AUTOSAR XML (schema 4-2-2)
standard types defined: boolean, float32, float64, sint16, sint32, sint64, sint8, uint16, uint32, uint64, uint8, void
package /BSW/ApplicationDataTypes
  333 x app type, all with category=VALUE:
    BattVolt_LBMR: compu {phys=raw*0.001 for raw 0..65534.99999999999; unit V}, range phys 0..65.535 V
    Day: range phys 0..31 Day
    DrvHeat1Sts: range phys 0..3
    DrvHeat1_pct: range phys 0..127
    DrvHeat2Sts: range phys 0..3
    DrvHeat2_pct: range phys 0..127
    DrvHeat3Sts: range phys 0..3
    DrvHeat3_pct: range phys 0..127
    DrvHeat4Sts: range phys 0..3
    DrvHeat4_pct: range phys 0..127
    DrvHeat5ErrSts: range phys 0..15
    DrvHeat5Sts: range phys 0..3
    DrvHeat5_pct: range phys 0..127
    DrvHeat6Sts: range phys 0..3
    DrvHeat6_pct: range phys 0..127
    DrvKneadingMassgLvlCmd10: range phys 0..3
    DrvKneadingMassgLvlCmd{5..9}: range phys 0..3
    DrvKneadingMassgSkillsCmd10: range phys 0..15
    DrvKneadingMassgSkillsCmd{5..9}: range phys 0..15
    DrvKneadingMassgSkillsSts10: range phys 0..15
    DrvKneadingMassgSkillsSts{5..9}: range phys 0..15
    DrvKneadingMassgTime10: compu {phys=raw*0.1 for raw 0..255}, range phys 0..25.5
    DrvKneadingMassgTime{5..9}: compu {phys=raw*0.1 for raw 0..255}, range phys 0..25.5
    DrvKneadingMassgTimesCmd10: range phys 0..15
    DrvKneadingMassgTimesCmd{5..9}: range phys 0..15
    DrvKneadingMassglvlSts10: range phys 0..3
    DrvKneadingMassglvlSts{5..9}: range phys 0..3
    DrvLumControlSts: range phys 0..7
    DrvLumSwitchSts: range phys 0..7
    DrvLumbarBottomWorkSts: range phys 0..3
    DrvLumbarMidWorkSts: range phys 0..3
    DrvLumbarTopWorkSts: range phys 0..3
    DrvMassSwitchSts: range phys 0..3
    DrvMassageHeatNTC1: compu {phys=raw*0.5-40 for raw -80..175; unit degC}, range phys -40..87.5 degC
    DrvMassageHeatNTC{10..12}: compu {phys=raw*0.5-40 for raw -80..175; unit degC}, range phys -40..87.5 degC
    DrvMassageHeatNTC{2..9}: compu {phys=raw*0.5-40 for raw -80..175; unit degC}, range phys -40..87.5 degC
    DrvPumpCmd: range phys 0..127
    DrvPumpSts: range phys 0..255
    DrvSeatBlosterValueSts: range phys 0..3
    DrvSeatBolsterValueBLCmd: range phys 0..3
    DrvSeatBolsterValueBLPos: range phys 0..255
    DrvSeatBolsterValueBRCmd: range phys 0..3
    DrvSeatBolsterValueBRPos: range phys 0..255
    DrvSeatCushionValue1Cmd: range phys 0..3
    DrvSeatCushionValue1Pos: range phys 0..255
    DrvSeatCushionValue2Cmd: range phys 0..3
    DrvSeatCushionValue2Pos: range phys 0..255
    DrvSeatCushionValue3Cmd: range phys 0..3
    DrvSeatCushionValue3Pos: range phys 0..100
    DrvSeatCushionValue4Cmd: range phys 0..3
    DrvSeatCushionValue4Pos: range phys 0..255
    DrvSeatCushionValue5Cmd: range phys 0..3
    DrvSeatCushionValue5Pos: range phys 0..255
    DrvSeatCushionValue6Cmd: range phys 0..3
    DrvSeatCushionValue6Pos: range phys 0..255
    DrvSeatCushionValueSts: range phys 0..3
    DrvSeatLumbarBottomPos: range phys 0..255
    DrvSeatLumbarBottomValue3Cmd: range phys 0..3
    DrvSeatLumbarMidPos: range phys 0..255
    DrvSeatLumbarMidValue2Cmd: range phys 0..3
    DrvSeatLumbarTopPos: range phys 0..255
    DrvSeatLumbarTopValue1Cmd: range phys 0..3
    DrvSeatLumbarValueSts: range phys 0..3
    DrvSeatMassFailr: range phys 0..1
    DrvSeatUpperValueLCmd: range phys 0..3
    DrvSeatUpperValueLPos: range phys 0..255
    DrvSeatUpperValueMCmd: range phys 0..3
    DrvSeatUpperValueMPos: range phys 0..255
    DrvSeatUpperValueRCmd: range phys 0..3
    DrvSeatUpperValueRPos: range phys 0..255
    DrvSeatUpperValueSts: range phys 0..3
    DrvSeatmassgHeat{10..12}Cmd: range phys 0..3
    DrvSeatmassgHeat{1..9}Cmd: range phys 0..3
    DrvSeatmassgHeatCSts: range phys 0..3
    DrvSeatmassgValve{10..12}Cmd: range phys 0..3
    DrvSeatmassgValve{1..9}Cmd: range phys 0..3
    DrvSeatmassgValveSts: range phys 0..3
    DrvState: range phys 0..7
    DrvState_SrvSts: range phys 0..1
    DrvSystemFailr: range phys 0..1
    Hr: range phys 0..23 Hour
    MSec: range phys 0..1023
    Min: range phys 0..59 min
    Mth: range phys 0..15
    OperatorState: range phys 0..7
    OperatorState_SrvSts: range phys 0..1
    PNC{10..19}_Sts: range phys 0..1
    PNC1_Sts: range phys 0..1
    PNC{20..29}_Sts: range phys 0..1
    PNC2_Sts: range phys 0..1
    PNC{30..39}_Sts: range phys 0..1
    PNC3_Sts: range phys 0..1
    PNC{40..48}_Sts: range phys 0..1
    PNC{4..9}_Sts: range phys 0..1
    PNC_DFT: range phys 0..1
    PassHeat1Sts: range phys 0..3
    PassHeat1_pct: range phys 0..127
    PassHeat2Sts: range phys 0..3
    PassHeat2_pct: range phys 0..127
    PassHeat3Sts: range phys 0..3
    PassHeat3_pct: range phys 0..127
    PassHeat4Sts: range phys 0..3
    PassHeat4_pct: range phys 0..127
    PassHeat5ErrSts: range phys 0..15
    PassHeat5Sts: range phys 0..3
    PassHeat5_pct: range phys 0..127
    PassHeat6Sts: range phys 0..3
    PassHeat6_pct: range phys 0..127
    PassKneadingMassgLvlCmd10: range phys 0..3
    PassKneadingMassgLvlCmd{5..9}: range phys 0..3
    PassKneadingMassgLvlSts10: range phys 0..3
    PassKneadingMassgLvlSts{5..9}: range phys 0..3
    PassKneadingMassgSkillsCmd10: range phys 0..15
    PassKneadingMassgSkillsCmd{5..9}: range phys 0..15
    PassKneadingMassgSkillsSts10: range phys 0..15
    PassKneadingMassgSkillsSts{5..9}: range phys 0..15
    PassKneadingMassgTime10: compu {phys=raw*0.1 for raw 0..255}, range phys 0..25.5
    PassKneadingMassgTime{5..9}: compu {phys=raw*0.1 for raw 0..255}, range phys 0..25.5
    PassKneadingMassgTimesCmd10: range phys 0..15
    PassKneadingMassgTimesCmd{5..9}: range phys 0..15
    PassLumControlSts: range phys 0..7
    PassLumSwitchSts: range phys 0..7
    PassLumbarBottomWorkSts: range phys 0..3
    PassLumbarMidWorkSts: range phys 0..3
    PassLumbarTopWorkSts: range phys 0..3
    PassMassSwitchSts: range phys 0..3
    PassMassageHeatNTC1: compu {phys=raw*0.5-40 for raw -80..175; unit degC}, range phys -40..87.5 degC
    PassMassageHeatNTC{10..12}: compu {phys=raw*0.5-40 for raw -80..175; unit degC}, range phys -40..87.5 degC
    PassMassageHeatNTC{2..9}: compu {phys=raw*0.5-40 for raw -80..175; unit degC}, range phys -40..87.5 degC
    PassPumpCmd: range phys 0..127
    PassPumpSts: range phys 0..255
    PassSeatBlosterValueSts: range phys 0..3
    PassSeatBolsterValueBLCmd: range phys 0..3
    PassSeatBolsterValueBLPos: range phys 0..255
    PassSeatBolsterValueBRCmd: range phys 0..3
    PassSeatBolsterValueBRPos: range phys 0..255
    PassSeatCushionValue1Cmd: range phys 0..3
    PassSeatCushionValue1Pos: range phys 0..255
    PassSeatCushionValue2Cmd: range phys 0..3
    PassSeatCushionValue2Pos: range phys 0..255
    PassSeatCushionValue3Cmd: range phys 0..3
    PassSeatCushionValue3Pos: range phys 0..100
    PassSeatCushionValue4Cmd: range phys 0..3
    PassSeatCushionValue4Pos: range phys 0..255
    PassSeatCushionValue5Cmd: range phys 0..3
    PassSeatCushionValue5Pos: range phys 0..255
    PassSeatCushionValue6Cmd: range phys 0..3
    PassSeatCushionValue6Pos: range phys 0..255
    PassSeatCushionValueSts: range phys 0..3
    PassSeatLumbarBottomPos: range phys 0..255
    PassSeatLumbarBottomValue3Cmd: range phys 0..3
    PassSeatLumbarMidPos: range phys 0..255
    PassSeatLumbarMidValue2Cmd: range phys 0..3
    PassSeatLumbarTopPos: range phys 0..255
    PassSeatLumbarTopValue1Cmd: range phys 0..3
    PassSeatLumbarValueSts: range phys 0..3
    PassSeatMassFailr: range phys 0..1
    PassSeatUpperValueLCmd: range phys 0..3
    PassSeatUpperValueLPos: range phys 0..255
    PassSeatUpperValueMCmd: range phys 0..3
    PassSeatUpperValueMPos: range phys 0..255
    PassSeatUpperValueRCmd: range phys 0..3
    PassSeatUpperValueRPos: range phys 0..255
    PassSeatUpperValueSts: range phys 0..3
    PassSeatmassgHeat{10..12}Cmd: range phys 0..3
    PassSeatmassgHeat{1..9}Cmd: range phys 0..3
    PassSeatmassgHeatCSts: range phys 0..3
    PassSeatmassgValve{10..12}Cmd: range phys 0..3
    PassSeatmassgValve{1..9}Cmd: range phys 0..3
    PassSeatmassgValveSts: range phys 0..3
    PassSystemFailr: range phys 0..1
    Sec: range phys 0..59 min
    VC_Data_5E0_CRC: range phys 0..255
    VC_Data_5E0_MsgCntr: range phys 0..14
    VC_Data_5E0_Payload: range phys 0..281474976710655
    VehModeDef: range phys 0..15
    VehOdometer: range phys 0..16777215 km
    VehSpdSts_Rdnt1: range phys 0..1
    VehSpd_Rdnt1: compu {phys=raw*0.05625 for raw 0..6400; unit km/h}, range phys 0..360 km/h
    VehStateDetailed: range phys 0..15
    VehStateDetailed_SrvSts: range phys 0..1
    Yr: compu {phys=raw+2000 for raw 2000..2254; unit Year}, range phys 2000..2254 Year
    ZONE_13C_CRC: range phys 0..255
    ZONE_13C_MsgCntr: range phys 0..14
    uint16: base-type=uint16
    uint32: base-type=uint32
    uint8: base-type=uint8
package /BSW/CompuMethods
  compu method CM_DrvHeat{1..4}Sts: 0=no_action, 1=action, 2=err, 3=reserved
  compu method CM_DrvHeat5ErrSts: 0=No_Error, 1=Heater_Short_to_GND, 2=Heater_short_to_PWR_or_Heater_Open, 3=Sensor_short_to_GND, 15=Invalid, 4=Sensor_short_to_PWR_or_Sensor_Open, 5=Over_Current
  compu method CM_DrvHeat5Sts: 0=no_action, 1=action, 2=err, 3=reserved
  compu method CM_DrvHeat6Sts: 0=no_action, 1=action, 2=err, 3=reserved
  compu method CM_DrvKneadingMassgLvlCmd10: 0=Idle, 1=intensity_1, 2=intensity_2
  compu method CM_DrvKneadingMassgLvlCmd{5..9}: 0=Idle, 1=intensity_1, 2=intensity_2
  compu method CM_DrvKneadingMassglvlSts10: 0=Idle, 1=intensity_1, 2=intensity_2
  compu method CM_DrvKneadingMassglvlSts{5..9}: 0=Idle, 1=intensity_1, 2=intensity_2
  compu method CM_DrvLumControlSts: 0=No_action, 1=Manual_control, 2=Recall, 3=System_failure, 4=Reserved
  compu method CM_DrvLumSwitchSts: 0=No_Press, 1=Forward, 2=Reward, 3=Up, 4=Down, 5=Erro
  compu method CM_DrvLumbarBottomWorkSts: 0=No_action, 1=Inflation, 2=Deflation, 3=Idle
  compu method CM_DrvLumbarMidWorkSts: 0=No_action, 1=Inflation, 2=Deflation, 3=Idle
  compu method CM_DrvLumbarTopWorkSts: 0=No_action, 1=Inflation, 2=Deflation, 3=Idle
  compu method CM_DrvMassSwitchSts: 0=No_Press, 1=Press, 2=Err, 3=Reserved
  compu method CM_DrvSeatBlosterValueSts: 0=Normal, 1=Action, 2=Err, 3=Reserved
  compu method CM_DrvSeatBolsterValueBLCmd: 0=No_action, 1=Inflation, 2=Deflation, 3=Reserved
  compu method CM_DrvSeatBolsterValueBRCmd: 0=No_action, 1=Inflation, 2=Deflation, 3=Reserved
  compu method CM_DrvSeatCushionValue{1..6}Cmd: 0=No_action, 1=Inflation, 2=Deflation, 3=Reserved
  compu method CM_DrvSeatCushionValueSts: 0=Normal, 1=Action, 2=Err, 3=Reserved
  compu method CM_DrvSeatLumbarBottomValue3Cmd: 0=No_action, 1=Inflation, 2=Deflation, 3=Reserved
  compu method CM_DrvSeatLumbarMidValue2Cmd: 0=No_action, 1=Inflation, 2=Deflation, 3=Reserved
  compu method CM_DrvSeatLumbarTopValue1Cmd: 0=No_action, 1=Inflation, 2=Deflation, 3=Reserved
  compu method CM_DrvSeatLumbarValueSts: 0=Normal, 1=Action, 2=Err, 3=Reserved
  compu method CM_DrvSeatMassFailr: 0=no_Failure, 1=Failure
  compu method CM_DrvSeatUpperValueLCmd: 0=No_action, 1=Inflation, 2=Deflation, 3=Reserved
  compu method CM_DrvSeatUpperValueMCmd: 0=No_action, 1=Inflation, 2=Deflation, 3=Reserved
  compu method CM_DrvSeatUpperValueRCmd: 0=No_action, 1=Inflation, 2=Deflation, 3=Reserved
  compu method CM_DrvSeatUpperValueSts: 0=Normal, 1=Action, 2=Err, 3=Reserved
  compu method CM_DrvSeatmassgHeat{10..12}Cmd: 0=No_action, 1=Heat_open, 2=Heat_Close, 3=Reserved
  compu method CM_DrvSeatmassgHeat{1..9}Cmd: 0=No_action, 1=Heat_open, 2=Heat_Close, 3=Reserved
  compu method CM_DrvSeatmassgHeatCSts: 0=Normal, 1=Action, 2=Err, 3=Reserved
  compu method CM_DrvSeatmassgValve{10..12}Cmd: 0=No_action, 1=Inflation, 2=Deflation, 3=Reserved
  compu method CM_DrvSeatmassgValve{1..9}Cmd: 0=No_action, 1=Inflation, 2=Deflation, 3=Reserved
  compu method CM_DrvSeatmassgValveSts: 0=Normal, 1=Action, 2=Err, 3=Reserved
  compu method CM_DrvState: 0=DRV_ST_NONE, 1=DRV_ST_MD, 2=DRV_ST_AD, 7=DRV_ST_INVALID
  compu method CM_DrvState_SrvSts: 0=invalid, 1=valid
  compu method CM_DrvSystemFailr: 0=no_Failure, 1=Failure
  compu method CM_Mth: 11=November, 12=December, 13=Reserved, 15=Invalid, 0=Unknown, 1=January, 2=February, 3=March, 4=April, 5=May, 6=June, 7=July, 8=August, 9=September, 10=October
  compu method CM_OperatorState: 0=OPERATOR_ST_NONE, 1=OPERATOR_ST_OUTSIDE, 2=OPERATOR_ST_AVAILABLE, 3=OPERATOR_ST_INSIDE, 7=OPERATOR_ST_INVALID
  compu method CM_OperatorState_SrvSts: 0=invalid, 1=valid
  compu method CM_PNC{10..19}_Sts: 0=Inactive, 1=Active
  compu method CM_PNC1_Sts: 0=Inactive, 1=Active
  compu method CM_PNC{20..29}_Sts: 0=Inactive, 1=Active
  compu method CM_PNC2_Sts: 0=Inactive, 1=Active
  compu method CM_PNC{30..39}_Sts: 0=Inactive, 1=Active
  compu method CM_PNC3_Sts: 0=Inactive, 1=Active
  compu method CM_PNC{40..48}_Sts: 0=Inactive, 1=Active
  compu method CM_PNC{4..9}_Sts: 0=Inactive, 1=Active
  compu method CM_PNC_DFT: 0=Inactive, 1=Active
  compu method CM_PassHeat{1..4}Sts: 0=no_action, 1=action, 2=err, 3=reserved
  compu method CM_PassHeat5ErrSts: 0=No_Error, 1=Heater_Short_to_GND, 2=Heater_short_to_PWR_or_Heater_Open, 3=Sensor_short_to_GND, 15=Invalid, 4=Sensor_short_to_PWR_or_Sensor_Open, 5=Over_Current
  compu method CM_PassHeat5Sts: 0=no_action, 1=action, 2=err, 3=reserved
  compu method CM_PassHeat6Sts: 0=no_action, 1=action, 2=err, 3=reserved
  compu method CM_PassKneadingMassgLvlCmd10: 0=Idle, 1=intensity_1, 2=intensity_2
  compu method CM_PassKneadingMassgLvlCmd{5..9}: 0=Idle, 1=intensity_1, 2=intensity_2
  compu method CM_PassKneadingMassgLvlSts10: 0=Idle, 1=intensity_1, 2=intensity_2
  compu method CM_PassKneadingMassgLvlSts{5..9}: 0=Idle, 1=intensity_1, 2=intensity_2
  compu method CM_PassLumControlSts: 0=No_action, 1=Manual_control, 2=Recall, 3=System_failure, 4=Reserved
  compu method CM_PassLumSwitchSts: 0=No_Press, 1=Forward, 2=Reward, 3=Up, 4=Down, 5=Erro
  compu method CM_PassLumbarBottomWorkSts: 0=No_action, 1=Inflation, 2=Deflation, 3=Idle
  compu method CM_PassLumbarMidWorkSts: 0=No_action, 1=Inflation, 2=Deflation, 3=Idle
  compu method CM_PassLumbarTopWorkSts: 0=No_action, 1=Inflation, 2=Deflation, 3=Idle
  compu method CM_PassMassSwitchSts: 0=No_Press, 1=Press, 2=Err, 3=Reserved
  compu method CM_PassSeatBlosterValueSts: 0=Normal, 1=Action, 2=Err, 3=Reserved
  compu method CM_PassSeatBolsterValueBLCmd: 0=No_action, 1=Inflation, 2=Deflation, 3=Reserved
  compu method CM_PassSeatBolsterValueBRCmd: 0=No_action, 1=Inflation, 2=Deflation, 3=Reserved
  compu method CM_PassSeatCushionValue{1..6}Cmd: 0=No_action, 1=Inflation, 2=Deflation, 3=Reserved
  compu method CM_PassSeatCushionValueSts: 0=Normal, 1=Action, 2=Err, 3=Reserved
  compu method CM_PassSeatLumbarBottomValue3Cmd: 0=No_action, 1=Inflation, 2=Deflation, 3=Reserved
  compu method CM_PassSeatLumbarMidValue2Cmd: 0=No_action, 1=Inflation, 2=Deflation, 3=Reserved
  compu method CM_PassSeatLumbarTopValue1Cmd: 0=No_action, 1=Inflation, 2=Deflation, 3=Reserved
  compu method CM_PassSeatLumbarValueSts: 0=Normal, 1=Action, 2=Err, 3=Reserved
  compu method CM_PassSeatMassFailr: 0=no_Failure, 1=Failure
  compu method CM_PassSeatUpperValueLCmd: 0=No_action, 1=Inflation, 2=Deflation, 3=Reserved
  compu method CM_PassSeatUpperValueMCmd: 0=No_action, 1=Inflation, 2=Deflation, 3=Reserved
  compu method CM_PassSeatUpperValueRCmd: 0=No_action, 1=Inflation, 2=Deflation, 3=Reserved
  compu method CM_PassSeatUpperValueSts: 0=Normal, 1=Action, 2=Err, 3=Reserved
  compu method CM_PassSeatmassgHeat{10..12}Cmd: 0=No_action, 1=Heat_open, 2=Heat_Close, 3=Reserved
  compu method CM_PassSeatmassgHeat{1..9}Cmd: 0=No_action, 1=Heat_open, 2=Heat_Close, 3=Reserved
  compu method CM_PassSeatmassgHeatCSts: 0=Normal, 1=Action, 2=Err, 3=Reserved
  compu method CM_PassSeatmassgValve{10..12}Cmd: 0=No_action, 1=Inflation, 2=Deflation, 3=Reserved
  compu method CM_PassSeatmassgValve{1..9}Cmd: 0=No_action, 1=Inflation, 2=Deflation, 3=Reserved
  compu method CM_PassSeatmassgValveSts: 0=Normal, 1=Action, 2=Err, 3=Reserved
  compu method CM_PassSystemFailr: 0=no_Failure, 1=Failure
  compu method CM_VehModeDef: 0=VEHMODE_RESERVED, 1=VEHMODE_PRODUCTION, 2=VEHMODE_TRANSPORT, 3=VEHMODE_SHOWROOM, 15=VEHMODE_INVALID, 4=VEHMODE_REGULAR, 5=VEHMODE_DUT, 6=VEHMODE_TESTDRIVE, 7=VEHMODE_MAINTENANCE, 8=VEHMODE_SVT, 9=VEHMODE_ENDOFLIFE
  compu method CM_VehSpdSts_Rdnt1: 0=Inalid, 1=Valid
  compu method CM_VehStateDetailed: 0=VEH_ST_PARKED, 1=VEH_ST_DRVRDY, 2=VEH_ST_DRIVING, 3=VEH_ST_SWUPDATE, 15=VEH_ST_INVALID, 4=VEH_ST_CHARGING, 5=VEH_ST_PWRSWAP
  compu method CM_VehStateDetailed_SrvSts: 0=invalid, 1=valid
package /BSW/ImplementationDataTypes
  330 x impl type, all with category=VALUE:
    BattVolt_LBMR_IDT: base-type=uint16
    Day_IDT: base-type=uint8
    DrvHeat1Sts_IDT: base-type=uint8
    DrvHeat1_pct_IDT: base-type=uint8
    DrvHeat2Sts_IDT: base-type=uint8
    DrvHeat2_pct_IDT: base-type=uint8
    DrvHeat3Sts_IDT: base-type=uint8
    DrvHeat3_pct_IDT: base-type=uint8
    DrvHeat4Sts_IDT: base-type=uint8
    DrvHeat4_pct_IDT: base-type=uint8
    DrvHeat5ErrSts_IDT: base-type=uint8
    DrvHeat5Sts_IDT: base-type=uint8
    DrvHeat5_pct_IDT: base-type=uint8
    DrvHeat6Sts_IDT: base-type=uint8
    DrvHeat6_pct_IDT: base-type=uint8
    DrvKneadingMassgLvlCmd10_IDT: base-type=uint8
    DrvKneadingMassgLvlCmd{5..9}_IDT: base-type=uint8
    DrvKneadingMassgSkillsCmd10_IDT: base-type=uint8
    DrvKneadingMassgSkillsCmd{5..9}_IDT: base-type=uint8
    DrvKneadingMassgSkillsSts10_IDT: base-type=uint8
    DrvKneadingMassgSkillsSts{5..9}_IDT: base-type=uint8
    DrvKneadingMassgTime10_IDT: base-type=uint8
    DrvKneadingMassgTime{5..9}_IDT: base-type=uint8
    DrvKneadingMassgTimesCmd10_IDT: base-type=uint8
    DrvKneadingMassgTimesCmd{5..9}_IDT: base-type=uint8
    DrvKneadingMassglvlSts10_IDT: base-type=uint8
    DrvKneadingMassglvlSts{5..9}_IDT: base-type=uint8
    DrvLumControlSts_IDT: base-type=uint8
    DrvLumSwitchSts_IDT: base-type=uint8
    DrvLumbarBottomWorkSts_IDT: base-type=uint8
    DrvLumbarMidWorkSts_IDT: base-type=uint8
    DrvLumbarTopWorkSts_IDT: base-type=uint8
    DrvMassSwitchSts_IDT: base-type=uint8
    DrvMassageHeatNTC{10..12}_IDT: base-type=uint8
    DrvMassageHeatNTC{1..9}_IDT: base-type=uint8
    DrvPumpCmd_IDT: base-type=uint8
    DrvPumpSts_IDT: base-type=uint8
    DrvSeatBlosterValueSts_IDT: base-type=uint8
    DrvSeatBolsterValueBLCmd_IDT: base-type=uint8
    DrvSeatBolsterValueBLPos_IDT: base-type=uint8
    DrvSeatBolsterValueBRCmd_IDT: base-type=uint8
    DrvSeatBolsterValueBRPos_IDT: base-type=uint8
    DrvSeatCushionValue1Cmd_IDT: base-type=uint8
    DrvSeatCushionValue1Pos_IDT: base-type=uint8
    DrvSeatCushionValue2Cmd_IDT: base-type=uint8
    DrvSeatCushionValue2Pos_IDT: base-type=uint8
    DrvSeatCushionValue3Cmd_IDT: base-type=uint8
    DrvSeatCushionValue3Pos_IDT: base-type=uint8
    DrvSeatCushionValue4Cmd_IDT: base-type=uint8
    DrvSeatCushionValue4Pos_IDT: base-type=uint8
    DrvSeatCushionValue5Cmd_IDT: base-type=uint8
    DrvSeatCushionValue5Pos_IDT: base-type=uint8
    DrvSeatCushionValue6Cmd_IDT: base-type=uint8
    DrvSeatCushionValue6Pos_IDT: base-type=uint8
    DrvSeatCushionValueSts_IDT: base-type=uint8
    DrvSeatLumbarBottomPos_IDT: base-type=uint8
    DrvSeatLumbarBottomValue3Cmd_IDT: base-type=uint8
    DrvSeatLumbarMidPos_IDT: base-type=uint8
    DrvSeatLumbarMidValue2Cmd_IDT: base-type=uint8
    DrvSeatLumbarTopPos_IDT: base-type=uint8
    DrvSeatLumbarTopValue1Cmd_IDT: base-type=uint8
    DrvSeatLumbarValueSts_IDT: base-type=uint8
    DrvSeatMassFailr_IDT: base-type=uint8
    DrvSeatUpperValueLCmd_IDT: base-type=uint8
    DrvSeatUpperValueLPos_IDT: base-type=uint8
    DrvSeatUpperValueMCmd_IDT: base-type=uint8
    DrvSeatUpperValueMPos_IDT: base-type=uint8
    DrvSeatUpperValueRCmd_IDT: base-type=uint8
    DrvSeatUpperValueRPos_IDT: base-type=uint8
    DrvSeatUpperValueSts_IDT: base-type=uint8
    DrvSeatmassgHeat{10..12}Cmd_IDT: base-type=uint8
    DrvSeatmassgHeat{1..9}Cmd_IDT: base-type=uint8
    DrvSeatmassgHeatCSts_IDT: base-type=uint8
    DrvSeatmassgValve{10..12}Cmd_IDT: base-type=uint8
    DrvSeatmassgValve{1..9}Cmd_IDT: base-type=uint8
    DrvSeatmassgValveSts_IDT: base-type=uint8
    DrvState_IDT: base-type=uint8
    DrvState_SrvSts_IDT: base-type=uint8
    DrvSystemFailr_IDT: base-type=uint8
    Hr_IDT: base-type=uint8
    MSec_IDT: base-type=uint16
    Min_IDT: base-type=uint8
    Mth_IDT: base-type=uint8
    OperatorState_IDT: base-type=uint8
    OperatorState_SrvSts_IDT: base-type=uint8
    PNC{10..19}_Sts_IDT: base-type=uint8
    PNC1_Sts_IDT: base-type=uint8
    PNC{20..29}_Sts_IDT: base-type=uint8
    PNC2_Sts_IDT: base-type=uint8
    PNC{30..39}_Sts_IDT: base-type=uint8
    PNC3_Sts_IDT: base-type=uint8
    PNC{40..48}_Sts_IDT: base-type=uint8
    PNC{4..9}_Sts_IDT: base-type=uint8
    PNC_DFT_IDT: base-type=uint8
    PassHeat1Sts_IDT: base-type=uint8
    PassHeat1_pct_IDT: base-type=uint8
    PassHeat2Sts_IDT: base-type=uint8
    PassHeat2_pct_IDT: base-type=uint8
    PassHeat3Sts_IDT: base-type=uint8
    PassHeat3_pct_IDT: base-type=uint8
    PassHeat4Sts_IDT: base-type=uint8
    PassHeat4_pct_IDT: base-type=uint8
    PassHeat5ErrSts_IDT: base-type=uint8
    PassHeat5Sts_IDT: base-type=uint8
    PassHeat5_pct_IDT: base-type=uint8
    PassHeat6Sts_IDT: base-type=uint8
    PassHeat6_pct_IDT: base-type=uint8
    PassKneadingMassgLvlCmd10_IDT: base-type=uint8
    PassKneadingMassgLvlCmd{5..9}_IDT: base-type=uint8
    PassKneadingMassgLvlSts10_IDT: base-type=uint8
    PassKneadingMassgLvlSts{5..9}_IDT: base-type=uint8
    PassKneadingMassgSkillsCmd10_IDT: base-type=uint8
    PassKneadingMassgSkillsCmd{5..9}_IDT: base-type=uint8
    PassKneadingMassgSkillsSts10_IDT: base-type=uint8
    PassKneadingMassgSkillsSts{5..9}_IDT: base-type=uint8
    PassKneadingMassgTime10_IDT: base-type=uint8
    PassKneadingMassgTime{5..9}_IDT: base-type=uint8
    PassKneadingMassgTimesCmd10_IDT: base-type=uint8
    PassKneadingMassgTimesCmd{5..9}_IDT: base-type=uint8
    PassLumControlSts_IDT: base-type=uint8
    PassLumSwitchSts_IDT: base-type=uint8
    PassLumbarBottomWorkSts_IDT: base-type=uint8
    PassLumbarMidWorkSts_IDT: base-type=uint8
    PassLumbarTopWorkSts_IDT: base-type=uint8
    PassMassSwitchSts_IDT: base-type=uint8
    PassMassageHeatNTC{10..12}_IDT: base-type=uint8
    PassMassageHeatNTC{1..9}_IDT: base-type=uint8
    PassPumpCmd_IDT: base-type=uint8
    PassPumpSts_IDT: base-type=uint8
    PassSeatBlosterValueSts_IDT: base-type=uint8
    PassSeatBolsterValueBLCmd_IDT: base-type=uint8
    PassSeatBolsterValueBLPos_IDT: base-type=uint8
    PassSeatBolsterValueBRCmd_IDT: base-type=uint8
    PassSeatBolsterValueBRPos_IDT: base-type=uint8
    PassSeatCushionValue1Cmd_IDT: base-type=uint8
    PassSeatCushionValue1Pos_IDT: base-type=uint8
    PassSeatCushionValue2Cmd_IDT: base-type=uint8
    PassSeatCushionValue2Pos_IDT: base-type=uint8
    PassSeatCushionValue3Cmd_IDT: base-type=uint8
    PassSeatCushionValue3Pos_IDT: base-type=uint8
    PassSeatCushionValue4Cmd_IDT: base-type=uint8
    PassSeatCushionValue4Pos_IDT: base-type=uint8
    PassSeatCushionValue5Cmd_IDT: base-type=uint8
    PassSeatCushionValue5Pos_IDT: base-type=uint8
    PassSeatCushionValue6Cmd_IDT: base-type=uint8
    PassSeatCushionValue6Pos_IDT: base-type=uint8
    PassSeatCushionValueSts_IDT: base-type=uint8
    PassSeatLumbarBottomPos_IDT: base-type=uint8
    PassSeatLumbarBottomValue3Cmd_IDT: base-type=uint8
    PassSeatLumbarMidPos_IDT: base-type=uint8
    PassSeatLumbarMidValue2Cmd_IDT: base-type=uint8
    PassSeatLumbarTopPos_IDT: base-type=uint8
    PassSeatLumbarTopValue1Cmd_IDT: base-type=uint8
    PassSeatLumbarValueSts_IDT: base-type=uint8
    PassSeatMassFailr_IDT: base-type=uint8
    PassSeatUpperValueLCmd_IDT: base-type=uint8
    PassSeatUpperValueLPos_IDT: base-type=uint8
    PassSeatUpperValueMCmd_IDT: base-type=uint8
    PassSeatUpperValueMPos_IDT: base-type=uint8
    PassSeatUpperValueRCmd_IDT: base-type=uint8
    PassSeatUpperValueRPos_IDT: base-type=uint8
    PassSeatUpperValueSts_IDT: base-type=uint8
    PassSeatmassgHeat{10..12}Cmd_IDT: base-type=uint8
    PassSeatmassgHeat{1..9}Cmd_IDT: base-type=uint8
    PassSeatmassgHeatCSts_IDT: base-type=uint8
    PassSeatmassgValve{10..12}Cmd_IDT: base-type=uint8
    PassSeatmassgValve{1..9}Cmd_IDT: base-type=uint8
    PassSeatmassgValveSts_IDT: base-type=uint8
    PassSystemFailr_IDT: base-type=uint8
    Sec_IDT: base-type=uint8
    VC_Data_5E0_CRC_IDT: base-type=uint8
    VC_Data_5E0_MsgCntr_IDT: base-type=uint8
    VC_Data_5E0_Payload_IDT: base-type=uint64
    VehModeDef_IDT: base-type=uint8
    VehOdometer_IDT: base-type=uint32
    VehSpdSts_Rdnt1_IDT: base-type=uint8
    VehSpd_Rdnt1_IDT: base-type=uint16
    VehStateDetailed_IDT: base-type=uint8
    VehStateDetailed_SrvSts_IDT: base-type=uint8
    Yr_IDT: base-type=uint8
    ZONE_13C_CRC_IDT: base-type=uint8
    ZONE_13C_MsgCntr_IDT: base-type=uint8
package /BSW/Units
  9 x unit:
    Day: display-name=Day
    Hour: display-name=Hour
    Sec: display-name=Sec
    V: display-name=V
    VehSpd_Rdnt1: display-name=km/h
    Year: display-name=Year
    degC: display-name=degC
    km: display-name=km
    min: display-name=min
package /BSW/PortInterfaces
  330 x sender receiver interface, all with service-kind=ANY-STANDARDIZED:
    BattVolt_LBMR
      data BattVolt_LBMR: type=BattVolt_LBMR
    Day
      data Day: type=Day
    DrvHeat1Sts
      data DrvHeat1Sts: type=DrvHeat1Sts
    DrvHeat1_pct
      data DrvHeat1_pct: type=DrvHeat1_pct
    DrvHeat2Sts
      data DrvHeat2Sts: type=DrvHeat2Sts
    DrvHeat2_pct
      data DrvHeat2_pct: type=DrvHeat2_pct
    DrvHeat3Sts
      data DrvHeat3Sts: type=DrvHeat3Sts
    DrvHeat3_pct
      data DrvHeat3_pct: type=DrvHeat3_pct
    DrvHeat4Sts
      data DrvHeat4Sts: type=DrvHeat4Sts
    DrvHeat4_pct
      data DrvHeat4_pct: type=DrvHeat4_pct
    DrvHeat5ErrSts
      data DrvHeat5ErrSts: type=DrvHeat5ErrSts
    DrvHeat5Sts
      data DrvHeat5Sts: type=DrvHeat5Sts
    DrvHeat5_pct
      data DrvHeat5_pct: type=DrvHeat5_pct
    DrvHeat6Sts
      data DrvHeat6Sts: type=DrvHeat6Sts
    DrvHeat6_pct
      data DrvHeat6_pct: type=DrvHeat6_pct
    DrvKneadingMassgLvlCmd10
      data DrvKneadingMassgLvlCmd10: type=DrvKneadingMassgLvlCmd10
    DrvKneadingMassgLvlCmd5
      data DrvKneadingMassgLvlCmd5: type=DrvKneadingMassgLvlCmd5
    DrvKneadingMassgLvlCmd6
      data DrvKneadingMassgLvlCmd6: type=DrvKneadingMassgLvlCmd6
    DrvKneadingMassgLvlCmd7
      data DrvKneadingMassgLvlCmd7: type=DrvKneadingMassgLvlCmd7
    DrvKneadingMassgLvlCmd8
      data DrvKneadingMassgLvlCmd8: type=DrvKneadingMassgLvlCmd8
    DrvKneadingMassgLvlCmd9
      data DrvKneadingMassgLvlCmd9: type=DrvKneadingMassgLvlCmd9
    DrvKneadingMassgSkillsCmd10
      data DrvKneadingMassgSkillsCmd10: type=DrvKneadingMassgSkillsCmd10
    DrvKneadingMassgSkillsCmd5
      data DrvKneadingMassgSkillsCmd5: type=DrvKneadingMassgSkillsCmd5
    DrvKneadingMassgSkillsCmd6
      data DrvKneadingMassgSkillsCmd6: type=DrvKneadingMassgSkillsCmd6
    DrvKneadingMassgSkillsCmd7
      data DrvKneadingMassgSkillsCmd7: type=DrvKneadingMassgSkillsCmd7
    DrvKneadingMassgSkillsCmd8
      data DrvKneadingMassgSkillsCmd8: type=DrvKneadingMassgSkillsCmd8
    DrvKneadingMassgSkillsCmd9
      data DrvKneadingMassgSkillsCmd9: type=DrvKneadingMassgSkillsCmd9
    DrvKneadingMassgSkillsSts10
      data DrvKneadingMassgSkillsSts10: type=DrvKneadingMassgSkillsSts10
    DrvKneadingMassgSkillsSts5
      data DrvKneadingMassgSkillsSts5: type=DrvKneadingMassgSkillsSts5
    DrvKneadingMassgSkillsSts6
      data DrvKneadingMassgSkillsSts6: type=DrvKneadingMassgSkillsSts6
    DrvKneadingMassgSkillsSts7
      data DrvKneadingMassgSkillsSts7: type=DrvKneadingMassgSkillsSts7
    DrvKneadingMassgSkillsSts8
      data DrvKneadingMassgSkillsSts8: type=DrvKneadingMassgSkillsSts8
    DrvKneadingMassgSkillsSts9
      data DrvKneadingMassgSkillsSts9: type=DrvKneadingMassgSkillsSts9
    DrvKneadingMassgTime10
      data DrvKneadingMassgTime10: type=DrvKneadingMassgTime10
    DrvKneadingMassgTime5
      data DrvKneadingMassgTime5: type=DrvKneadingMassgTime5
    DrvKneadingMassgTime6
      data DrvKneadingMassgTime6: type=DrvKneadingMassgTime6
    DrvKneadingMassgTime7
      data DrvKneadingMassgTime7: type=DrvKneadingMassgTime7
    DrvKneadingMassgTime8
      data DrvKneadingMassgTime8: type=DrvKneadingMassgTime8
    DrvKneadingMassgTime9
      data DrvKneadingMassgTime9: type=DrvKneadingMassgTime9
    DrvKneadingMassgTimesCmd10
      data DrvKneadingMassgTimesCmd10: type=DrvKneadingMassgTimesCmd10
    DrvKneadingMassgTimesCmd5
      data DrvKneadingMassgTimesCmd5: type=DrvKneadingMassgTimesCmd5
    DrvKneadingMassgTimesCmd6
      data DrvKneadingMassgTimesCmd6: type=DrvKneadingMassgTimesCmd6
    DrvKneadingMassgTimesCmd7
      data DrvKneadingMassgTimesCmd7: type=DrvKneadingMassgTimesCmd7
    DrvKneadingMassgTimesCmd8
      data DrvKneadingMassgTimesCmd8: type=DrvKneadingMassgTimesCmd8
    DrvKneadingMassgTimesCmd9
      data DrvKneadingMassgTimesCmd9: type=DrvKneadingMassgTimesCmd9
    DrvKneadingMassglvlSts10
      data DrvKneadingMassglvlSts10: type=DrvKneadingMassglvlSts10
    DrvKneadingMassglvlSts5
      data DrvKneadingMassglvlSts5: type=DrvKneadingMassglvlSts5
    DrvKneadingMassglvlSts6
      data DrvKneadingMassglvlSts6: type=DrvKneadingMassglvlSts6
    DrvKneadingMassglvlSts7
      data DrvKneadingMassglvlSts7: type=DrvKneadingMassglvlSts7
    DrvKneadingMassglvlSts8
      data DrvKneadingMassglvlSts8: type=DrvKneadingMassglvlSts8
    DrvKneadingMassglvlSts9
      data DrvKneadingMassglvlSts9: type=DrvKneadingMassglvlSts9
    DrvLumControlSts
      data DrvLumControlSts: type=DrvLumControlSts
    DrvLumSwitchSts
      data DrvLumSwitchSts: type=DrvLumSwitchSts
    DrvLumbarBottomWorkSts
      data DrvLumbarBottomWorkSts: type=DrvLumbarBottomWorkSts
    DrvLumbarMidWorkSts
      data DrvLumbarMidWorkSts: type=DrvLumbarMidWorkSts
    DrvLumbarTopWorkSts
      data DrvLumbarTopWorkSts: type=DrvLumbarTopWorkSts
    DrvMassSwitchSts
      data DrvMassSwitchSts: type=DrvMassSwitchSts
    DrvMassageHeatNTC1
      data DrvMassageHeatNTC1: type=DrvMassageHeatNTC1
    DrvMassageHeatNTC10
      data DrvMassageHeatNTC10: type=DrvMassageHeatNTC10
    DrvMassageHeatNTC11
      data DrvMassageHeatNTC11: type=DrvMassageHeatNTC11
    DrvMassageHeatNTC12
      data DrvMassageHeatNTC12: type=DrvMassageHeatNTC12
    DrvMassageHeatNTC2
      data DrvMassageHeatNTC2: type=DrvMassageHeatNTC2
    DrvMassageHeatNTC3
      data DrvMassageHeatNTC3: type=DrvMassageHeatNTC3
    DrvMassageHeatNTC4
      data DrvMassageHeatNTC4: type=DrvMassageHeatNTC4
    DrvMassageHeatNTC5
      data DrvMassageHeatNTC5: type=DrvMassageHeatNTC5
    DrvMassageHeatNTC6
      data DrvMassageHeatNTC6: type=DrvMassageHeatNTC6
    DrvMassageHeatNTC7
      data DrvMassageHeatNTC7: type=DrvMassageHeatNTC7
    DrvMassageHeatNTC8
      data DrvMassageHeatNTC8: type=DrvMassageHeatNTC8
    DrvMassageHeatNTC9
      data DrvMassageHeatNTC9: type=DrvMassageHeatNTC9
    DrvPumpCmd
      data DrvPumpCmd: type=DrvPumpCmd
    DrvPumpSts
      data DrvPumpSts: type=DrvPumpSts
    DrvSeatBlosterValueSts
      data DrvSeatBlosterValueSts: type=DrvSeatBlosterValueSts
    DrvSeatBolsterValueBLCmd
      data DrvSeatBolsterValueBLCmd: type=DrvSeatBolsterValueBLCmd
    DrvSeatBolsterValueBLPos
      data DrvSeatBolsterValueBLPos: type=DrvSeatBolsterValueBLPos
    DrvSeatBolsterValueBRCmd
      data DrvSeatBolsterValueBRCmd: type=DrvSeatBolsterValueBRCmd
    DrvSeatBolsterValueBRPos
      data DrvSeatBolsterValueBRPos: type=DrvSeatBolsterValueBRPos
    DrvSeatCushionValue1Cmd
      data DrvSeatCushionValue1Cmd: type=DrvSeatCushionValue1Cmd
    DrvSeatCushionValue1Pos
      data DrvSeatCushionValue1Pos: type=DrvSeatCushionValue1Pos
    DrvSeatCushionValue2Cmd
      data DrvSeatCushionValue2Cmd: type=DrvSeatCushionValue2Cmd
    DrvSeatCushionValue2Pos
      data DrvSeatCushionValue2Pos: type=DrvSeatCushionValue2Pos
    DrvSeatCushionValue3Cmd
      data DrvSeatCushionValue3Cmd: type=DrvSeatCushionValue3Cmd
    DrvSeatCushionValue3Pos
      data DrvSeatCushionValue3Pos: type=DrvSeatCushionValue3Pos
    DrvSeatCushionValue4Cmd
      data DrvSeatCushionValue4Cmd: type=DrvSeatCushionValue4Cmd
    DrvSeatCushionValue4Pos
      data DrvSeatCushionValue4Pos: type=DrvSeatCushionValue4Pos
    DrvSeatCushionValue5Cmd
      data DrvSeatCushionValue5Cmd: type=DrvSeatCushionValue5Cmd
    DrvSeatCushionValue5Pos
      data DrvSeatCushionValue5Pos: type=DrvSeatCushionValue5Pos
    DrvSeatCushionValue6Cmd
      data DrvSeatCushionValue6Cmd: type=DrvSeatCushionValue6Cmd
    DrvSeatCushionValue6Pos
      data DrvSeatCushionValue6Pos: type=DrvSeatCushionValue6Pos
    DrvSeatCushionValueSts
      data DrvSeatCushionValueSts: type=DrvSeatCushionValueSts
    DrvSeatLumbarBottomPos
      data DrvSeatLumbarBottomPos: type=DrvSeatLumbarBottomPos
    DrvSeatLumbarBottomValue3Cmd
      data DrvSeatLumbarBottomValue3Cmd: type=DrvSeatLumbarBottomValue3Cmd
    DrvSeatLumbarMidPos
      data DrvSeatLumbarMidPos: type=DrvSeatLumbarMidPos
    DrvSeatLumbarMidValue2Cmd
      data DrvSeatLumbarMidValue2Cmd: type=DrvSeatLumbarMidValue2Cmd
    DrvSeatLumbarTopPos
      data DrvSeatLumbarTopPos: type=DrvSeatLumbarTopPos
    DrvSeatLumbarTopValue1Cmd
      data DrvSeatLumbarTopValue1Cmd: type=DrvSeatLumbarTopValue1Cmd
    DrvSeatLumbarValueSts
      data DrvSeatLumbarValueSts: type=DrvSeatLumbarValueSts
    DrvSeatMassFailr
      data DrvSeatMassFailr: type=DrvSeatMassFailr
    DrvSeatUpperValueLCmd
      data DrvSeatUpperValueLCmd: type=DrvSeatUpperValueLCmd
    DrvSeatUpperValueLPos
      data DrvSeatUpperValueLPos: type=DrvSeatUpperValueLPos
    DrvSeatUpperValueMCmd
      data DrvSeatUpperValueMCmd: type=DrvSeatUpperValueMCmd
    DrvSeatUpperValueMPos
      data DrvSeatUpperValueMPos: type=DrvSeatUpperValueMPos
    DrvSeatUpperValueRCmd
      data DrvSeatUpperValueRCmd: type=DrvSeatUpperValueRCmd
    DrvSeatUpperValueRPos
      data DrvSeatUpperValueRPos: type=DrvSeatUpperValueRPos
    DrvSeatUpperValueSts
      data DrvSeatUpperValueSts: type=DrvSeatUpperValueSts
    DrvSeatmassgHeat10Cmd
      data DrvSeatmassgHeat10Cmd: type=DrvSeatmassgHeat10Cmd
    DrvSeatmassgHeat11Cmd
      data DrvSeatmassgHeat11Cmd: type=DrvSeatmassgHeat11Cmd
    DrvSeatmassgHeat12Cmd
      data DrvSeatmassgHeat12Cmd: type=DrvSeatmassgHeat12Cmd
    DrvSeatmassgHeat1Cmd
      data DrvSeatmassgHeat1Cmd: type=DrvSeatmassgHeat1Cmd
    DrvSeatmassgHeat2Cmd
      data DrvSeatmassgHeat2Cmd: type=DrvSeatmassgHeat2Cmd
    DrvSeatmassgHeat3Cmd
      data DrvSeatmassgHeat3Cmd: type=DrvSeatmassgHeat3Cmd
    DrvSeatmassgHeat4Cmd
      data DrvSeatmassgHeat4Cmd: type=DrvSeatmassgHeat4Cmd
    DrvSeatmassgHeat5Cmd
      data DrvSeatmassgHeat5Cmd: type=DrvSeatmassgHeat5Cmd
    DrvSeatmassgHeat6Cmd
      data DrvSeatmassgHeat6Cmd: type=DrvSeatmassgHeat6Cmd
    DrvSeatmassgHeat7Cmd
      data DrvSeatmassgHeat7Cmd: type=DrvSeatmassgHeat7Cmd
    DrvSeatmassgHeat8Cmd
      data DrvSeatmassgHeat8Cmd: type=DrvSeatmassgHeat8Cmd
    DrvSeatmassgHeat9Cmd
      data DrvSeatmassgHeat9Cmd: type=DrvSeatmassgHeat9Cmd
    DrvSeatmassgHeatCSts
      data DrvSeatmassgHeatCSts: type=DrvSeatmassgHeatCSts
    DrvSeatmassgValve10Cmd
      data DrvSeatmassgValve10Cmd: type=DrvSeatmassgValve10Cmd
    DrvSeatmassgValve11Cmd
      data DrvSeatmassgValve11Cmd: type=DrvSeatmassgValve11Cmd
    DrvSeatmassgValve12Cmd
      data DrvSeatmassgValve12Cmd: type=DrvSeatmassgValve12Cmd
    DrvSeatmassgValve1Cmd
      data DrvSeatmassgValve1Cmd: type=DrvSeatmassgValve1Cmd
    DrvSeatmassgValve2Cmd
      data DrvSeatmassgValve2Cmd: type=DrvSeatmassgValve2Cmd
    DrvSeatmassgValve3Cmd
      data DrvSeatmassgValve3Cmd: type=DrvSeatmassgValve3Cmd
    DrvSeatmassgValve4Cmd
      data DrvSeatmassgValve4Cmd: type=DrvSeatmassgValve4Cmd
    DrvSeatmassgValve5Cmd
      data DrvSeatmassgValve5Cmd: type=DrvSeatmassgValve5Cmd
    DrvSeatmassgValve6Cmd
      data DrvSeatmassgValve6Cmd: type=DrvSeatmassgValve6Cmd
    DrvSeatmassgValve7Cmd
      data DrvSeatmassgValve7Cmd: type=DrvSeatmassgValve7Cmd
    DrvSeatmassgValve8Cmd
      data DrvSeatmassgValve8Cmd: type=DrvSeatmassgValve8Cmd
    DrvSeatmassgValve9Cmd
      data DrvSeatmassgValve9Cmd: type=DrvSeatmassgValve9Cmd
    DrvSeatmassgValveSts
      data DrvSeatmassgValveSts: type=DrvSeatmassgValveSts
    DrvState
      data DrvState: type=DrvState
    DrvState_SrvSts
      data DrvState_SrvSts: type=DrvState_SrvSts
    DrvSystemFailr
      data DrvSystemFailr: type=DrvSystemFailr
    Hr
      data Hr: type=Hr
    MSec
      data MSec: type=MSec
    Min
      data Min: type=Min
    Mth
      data Mth: type=Mth
    OperatorState
      data OperatorState: type=OperatorState
    OperatorState_SrvSts
      data OperatorState_SrvSts: type=OperatorState_SrvSts
    PNC10_Sts
      data PNC10_Sts: type=PNC10_Sts
    PNC11_Sts
      data PNC11_Sts: type=PNC11_Sts
    PNC12_Sts
      data PNC12_Sts: type=PNC12_Sts
    PNC13_Sts
      data PNC13_Sts: type=PNC13_Sts
    PNC14_Sts
      data PNC14_Sts: type=PNC14_Sts
    PNC15_Sts
      data PNC15_Sts: type=PNC15_Sts
    PNC16_Sts
      data PNC16_Sts: type=PNC16_Sts
    PNC17_Sts
      data PNC17_Sts: type=PNC17_Sts
    PNC18_Sts
      data PNC18_Sts: type=PNC18_Sts
    PNC19_Sts
      data PNC19_Sts: type=PNC19_Sts
    PNC1_Sts
      data PNC1_Sts: type=PNC1_Sts
    PNC20_Sts
      data PNC20_Sts: type=PNC20_Sts
    PNC21_Sts
      data PNC21_Sts: type=PNC21_Sts
    PNC22_Sts
      data PNC22_Sts: type=PNC22_Sts
    PNC23_Sts
      data PNC23_Sts: type=PNC23_Sts
    PNC24_Sts
      data PNC24_Sts: type=PNC24_Sts
    PNC25_Sts
      data PNC25_Sts: type=PNC25_Sts
    PNC26_Sts
      data PNC26_Sts: type=PNC26_Sts
    PNC27_Sts
      data PNC27_Sts: type=PNC27_Sts
    PNC28_Sts
      data PNC28_Sts: type=PNC28_Sts
    PNC29_Sts
      data PNC29_Sts: type=PNC29_Sts
    PNC2_Sts
      data PNC2_Sts: type=PNC2_Sts
    PNC30_Sts
      data PNC30_Sts: type=PNC30_Sts
    PNC31_Sts
      data PNC31_Sts: type=PNC31_Sts
    PNC32_Sts
      data PNC32_Sts: type=PNC32_Sts
    PNC33_Sts
      data PNC33_Sts: type=PNC33_Sts
    PNC34_Sts
      data PNC34_Sts: type=PNC34_Sts
    PNC35_Sts
      data PNC35_Sts: type=PNC35_Sts
    PNC36_Sts
      data PNC36_Sts: type=PNC36_Sts
    PNC37_Sts
      data PNC37_Sts: type=PNC37_Sts
    PNC38_Sts
      data PNC38_Sts: type=PNC38_Sts
    PNC39_Sts
      data PNC39_Sts: type=PNC39_Sts
    PNC3_Sts
      data PNC3_Sts: type=PNC3_Sts
    PNC40_Sts
      data PNC40_Sts: type=PNC40_Sts
    PNC41_Sts
      data PNC41_Sts: type=PNC41_Sts
    PNC42_Sts
      data PNC42_Sts: type=PNC42_Sts
    PNC43_Sts
      data PNC43_Sts: type=PNC43_Sts
    PNC44_Sts
      data PNC44_Sts: type=PNC44_Sts
    PNC45_Sts
      data PNC45_Sts: type=PNC45_Sts
    PNC46_Sts
      data PNC46_Sts: type=PNC46_Sts
    PNC47_Sts
      data PNC47_Sts: type=PNC47_Sts
    PNC48_Sts
      data PNC48_Sts: type=PNC48_Sts
    PNC4_Sts
      data PNC4_Sts: type=PNC4_Sts
    PNC5_Sts
      data PNC5_Sts: type=PNC5_Sts
    PNC6_Sts
      data PNC6_Sts: type=PNC6_Sts
    PNC7_Sts
      data PNC7_Sts: type=PNC7_Sts
    PNC8_Sts
      data PNC8_Sts: type=PNC8_Sts
    PNC9_Sts
      data PNC9_Sts: type=PNC9_Sts
    PNC_DFT
      data PNC_DFT: type=PNC_DFT
    PassHeat1Sts
      data PassHeat1Sts: type=PassHeat1Sts
    PassHeat1_pct
      data PassHeat1_pct: type=PassHeat1_pct
    PassHeat2Sts
      data PassHeat2Sts: type=PassHeat2Sts
    PassHeat2_pct
      data PassHeat2_pct: type=PassHeat2_pct
    PassHeat3Sts
      data PassHeat3Sts: type=PassHeat3Sts
    PassHeat3_pct
      data PassHeat3_pct: type=PassHeat3_pct
    PassHeat4Sts
      data PassHeat4Sts: type=PassHeat4Sts
    PassHeat4_pct
      data PassHeat4_pct: type=PassHeat4_pct
    PassHeat5ErrSts
      data PassHeat5ErrSts: type=PassHeat5ErrSts
    PassHeat5Sts
      data PassHeat5Sts: type=PassHeat5Sts
    PassHeat5_pct
      data PassHeat5_pct: type=PassHeat5_pct
    PassHeat6Sts
      data PassHeat6Sts: type=PassHeat6Sts
    PassHeat6_pct
      data PassHeat6_pct: type=PassHeat6_pct
    PassKneadingMassgLvlCmd10
      data PassKneadingMassgLvlCmd10: type=PassKneadingMassgLvlCmd10
    PassKneadingMassgLvlCmd5
      data PassKneadingMassgLvlCmd5: type=PassKneadingMassgLvlCmd5
    PassKneadingMassgLvlCmd6
      data PassKneadingMassgLvlCmd6: type=PassKneadingMassgLvlCmd6
    PassKneadingMassgLvlCmd7
      data PassKneadingMassgLvlCmd7: type=PassKneadingMassgLvlCmd7
    PassKneadingMassgLvlCmd8
      data PassKneadingMassgLvlCmd8: type=PassKneadingMassgLvlCmd8
    PassKneadingMassgLvlCmd9
      data PassKneadingMassgLvlCmd9: type=PassKneadingMassgLvlCmd9
    PassKneadingMassgLvlSts10
      data PassKneadingMassgLvlSts10: type=PassKneadingMassgLvlSts10
    PassKneadingMassgLvlSts5
      data PassKneadingMassgLvlSts5: type=PassKneadingMassgLvlSts5
    PassKneadingMassgLvlSts6
      data PassKneadingMassgLvlSts6: type=PassKneadingMassgLvlSts6
    PassKneadingMassgLvlSts7
      data PassKneadingMassgLvlSts7: type=PassKneadingMassgLvlSts7
    PassKneadingMassgLvlSts8
      data PassKneadingMassgLvlSts8: type=PassKneadingMassgLvlSts8
    PassKneadingMassgLvlSts9
      data PassKneadingMassgLvlSts9: type=PassKneadingMassgLvlSts9
    PassKneadingMassgSkillsCmd10
      data PassKneadingMassgSkillsCmd10: type=PassKneadingMassgSkillsCmd10
    PassKneadingMassgSkillsCmd5
      data PassKneadingMassgSkillsCmd5: type=PassKneadingMassgSkillsCmd5
    PassKneadingMassgSkillsCmd6
      data PassKneadingMassgSkillsCmd6: type=PassKneadingMassgSkillsCmd6
    PassKneadingMassgSkillsCmd7
      data PassKneadingMassgSkillsCmd7: type=PassKneadingMassgSkillsCmd7
    PassKneadingMassgSkillsCmd8
      data PassKneadingMassgSkillsCmd8: type=PassKneadingMassgSkillsCmd8
    PassKneadingMassgSkillsCmd9
      data PassKneadingMassgSkillsCmd9: type=PassKneadingMassgSkillsCmd9
    PassKneadingMassgSkillsSts10
      data PassKneadingMassgSkillsSts10: type=PassKneadingMassgSkillsSts10
    PassKneadingMassgSkillsSts5
      data PassKneadingMassgSkillsSts5: type=PassKneadingMassgSkillsSts5
    PassKneadingMassgSkillsSts6
      data PassKneadingMassgSkillsSts6: type=PassKneadingMassgSkillsSts6
    PassKneadingMassgSkillsSts7
      data PassKneadingMassgSkillsSts7: type=PassKneadingMassgSkillsSts7
    PassKneadingMassgSkillsSts8
      data PassKneadingMassgSkillsSts8: type=PassKneadingMassgSkillsSts8
    PassKneadingMassgSkillsSts9
      data PassKneadingMassgSkillsSts9: type=PassKneadingMassgSkillsSts9
    PassKneadingMassgTime10
      data PassKneadingMassgTime10: type=PassKneadingMassgTime10
    PassKneadingMassgTime5
      data PassKneadingMassgTime5: type=PassKneadingMassgTime5
    PassKneadingMassgTime6
      data PassKneadingMassgTime6: type=PassKneadingMassgTime6
    PassKneadingMassgTime7
      data PassKneadingMassgTime7: type=PassKneadingMassgTime7
    PassKneadingMassgTime8
      data PassKneadingMassgTime8: type=PassKneadingMassgTime8
    PassKneadingMassgTime9
      data PassKneadingMassgTime9: type=PassKneadingMassgTime9
    PassKneadingMassgTimesCmd10
      data PassKneadingMassgTimesCmd10: type=PassKneadingMassgTimesCmd10
    PassKneadingMassgTimesCmd5
      data PassKneadingMassgTimesCmd5: type=PassKneadingMassgTimesCmd5
    PassKneadingMassgTimesCmd6
      data PassKneadingMassgTimesCmd6: type=PassKneadingMassgTimesCmd6
    PassKneadingMassgTimesCmd7
      data PassKneadingMassgTimesCmd7: type=PassKneadingMassgTimesCmd7
    PassKneadingMassgTimesCmd8
      data PassKneadingMassgTimesCmd8: type=PassKneadingMassgTimesCmd8
    PassKneadingMassgTimesCmd9
      data PassKneadingMassgTimesCmd9: type=PassKneadingMassgTimesCmd9
    PassLumControlSts
      data PassLumControlSts: type=PassLumControlSts
    PassLumSwitchSts
      data PassLumSwitchSts: type=PassLumSwitchSts
    PassLumbarBottomWorkSts
      data PassLumbarBottomWorkSts: type=PassLumbarBottomWorkSts
    PassLumbarMidWorkSts
      data PassLumbarMidWorkSts: type=PassLumbarMidWorkSts
    PassLumbarTopWorkSts
      data PassLumbarTopWorkSts: type=PassLumbarTopWorkSts
    PassMassSwitchSts
      data PassMassSwitchSts: type=PassMassSwitchSts
    PassMassageHeatNTC1
      data PassMassageHeatNTC1: type=PassMassageHeatNTC1
    PassMassageHeatNTC10
      data PassMassageHeatNTC10: type=PassMassageHeatNTC10
    PassMassageHeatNTC11
      data PassMassageHeatNTC11: type=PassMassageHeatNTC11
    PassMassageHeatNTC12
      data PassMassageHeatNTC12: type=PassMassageHeatNTC12
    PassMassageHeatNTC2
      data PassMassageHeatNTC2: type=PassMassageHeatNTC2
    PassMassageHeatNTC3
      data PassMassageHeatNTC3: type=PassMassageHeatNTC3
    PassMassageHeatNTC4
      data PassMassageHeatNTC4: type=PassMassageHeatNTC4
    PassMassageHeatNTC5
      data PassMassageHeatNTC5: type=PassMassageHeatNTC5
    PassMassageHeatNTC6
      data PassMassageHeatNTC6: type=PassMassageHeatNTC6
    PassMassageHeatNTC7
      data PassMassageHeatNTC7: type=PassMassageHeatNTC7
    PassMassageHeatNTC8
      data PassMassageHeatNTC8: type=PassMassageHeatNTC8
    PassMassageHeatNTC9
      data PassMassageHeatNTC9: type=PassMassageHeatNTC9
    PassPumpCmd
      data PassPumpCmd: type=PassPumpCmd
    PassPumpSts
      data PassPumpSts: type=PassPumpSts
    PassSeatBlosterValueSts
      data PassSeatBlosterValueSts: type=PassSeatBlosterValueSts
    PassSeatBolsterValueBLCmd
      data PassSeatBolsterValueBLCmd: type=PassSeatBolsterValueBLCmd
    PassSeatBolsterValueBLPos
      data PassSeatBolsterValueBLPos: type=PassSeatBolsterValueBLPos
    PassSeatBolsterValueBRCmd
      data PassSeatBolsterValueBRCmd: type=PassSeatBolsterValueBRCmd
    PassSeatBolsterValueBRPos
      data PassSeatBolsterValueBRPos: type=PassSeatBolsterValueBRPos
    PassSeatCushionValue1Cmd
      data PassSeatCushionValue1Cmd: type=PassSeatCushionValue1Cmd
    PassSeatCushionValue1Pos
      data PassSeatCushionValue1Pos: type=PassSeatCushionValue1Pos
    PassSeatCushionValue2Cmd
      data PassSeatCushionValue2Cmd: type=PassSeatCushionValue2Cmd
    PassSeatCushionValue2Pos
      data PassSeatCushionValue2Pos: type=PassSeatCushionValue2Pos
    PassSeatCushionValue3Cmd
      data PassSeatCushionValue3Cmd: type=PassSeatCushionValue3Cmd
    PassSeatCushionValue3Pos
      data PassSeatCushionValue3Pos: type=PassSeatCushionValue3Pos
    PassSeatCushionValue4Cmd
      data PassSeatCushionValue4Cmd: type=PassSeatCushionValue4Cmd
    PassSeatCushionValue4Pos
      data PassSeatCushionValue4Pos: type=PassSeatCushionValue4Pos
    PassSeatCushionValue5Cmd
      data PassSeatCushionValue5Cmd: type=PassSeatCushionValue5Cmd
    PassSeatCushionValue5Pos
      data PassSeatCushionValue5Pos: type=PassSeatCushionValue5Pos
    PassSeatCushionValue6Cmd
      data PassSeatCushionValue6Cmd: type=PassSeatCushionValue6Cmd
    PassSeatCushionValue6Pos
      data PassSeatCushionValue6Pos: type=PassSeatCushionValue6Pos
    PassSeatCushionValueSts
      data PassSeatCushionValueSts: type=PassSeatCushionValueSts
    PassSeatLumbarBottomPos
      data PassSeatLumbarBottomPos: type=PassSeatLumbarBottomPos
    PassSeatLumbarBottomValue3Cmd
      data PassSeatLumbarBottomValue3Cmd: type=PassSeatLumbarBottomValue3Cmd
    PassSeatLumbarMidPos
      data PassSeatLumbarMidPos: type=PassSeatLumbarMidPos
    PassSeatLumbarMidValue2Cmd
      data PassSeatLumbarMidValue2Cmd: type=PassSeatLumbarMidValue2Cmd
    PassSeatLumbarTopPos
      data PassSeatLumbarTopPos: type=PassSeatLumbarTopPos
    PassSeatLumbarTopValue1Cmd
      data PassSeatLumbarTopValue1Cmd: type=PassSeatLumbarTopValue1Cmd
    PassSeatLumbarValueSts
      data PassSeatLumbarValueSts: type=PassSeatLumbarValueSts
    PassSeatMassFailr
      data PassSeatMassFailr: type=PassSeatMassFailr
    PassSeatUpperValueLCmd
      data PassSeatUpperValueLCmd: type=PassSeatUpperValueLCmd
    PassSeatUpperValueLPos
      data PassSeatUpperValueLPos: type=PassSeatUpperValueLPos
    PassSeatUpperValueMCmd
      data PassSeatUpperValueMCmd: type=PassSeatUpperValueMCmd
    PassSeatUpperValueMPos
      data PassSeatUpperValueMPos: type=PassSeatUpperValueMPos
    PassSeatUpperValueRCmd
      data PassSeatUpperValueRCmd: type=PassSeatUpperValueRCmd
    PassSeatUpperValueRPos
      data PassSeatUpperValueRPos: type=PassSeatUpperValueRPos
    PassSeatUpperValueSts
      data PassSeatUpperValueSts: type=PassSeatUpperValueSts
    PassSeatmassgHeat10Cmd
      data PassSeatmassgHeat10Cmd: type=PassSeatmassgHeat10Cmd
    PassSeatmassgHeat11Cmd
      data PassSeatmassgHeat11Cmd: type=PassSeatmassgHeat11Cmd
    PassSeatmassgHeat12Cmd
      data PassSeatmassgHeat12Cmd: type=PassSeatmassgHeat12Cmd
    PassSeatmassgHeat1Cmd
      data PassSeatmassgHeat1Cmd: type=PassSeatmassgHeat1Cmd
    PassSeatmassgHeat2Cmd
      data PassSeatmassgHeat2Cmd: type=PassSeatmassgHeat2Cmd
    PassSeatmassgHeat3Cmd
      data PassSeatmassgHeat3Cmd: type=PassSeatmassgHeat3Cmd
    PassSeatmassgHeat4Cmd
      data PassSeatmassgHeat4Cmd: type=PassSeatmassgHeat4Cmd
    PassSeatmassgHeat5Cmd
      data PassSeatmassgHeat5Cmd: type=PassSeatmassgHeat5Cmd
    PassSeatmassgHeat6Cmd
      data PassSeatmassgHeat6Cmd: type=PassSeatmassgHeat6Cmd
    PassSeatmassgHeat7Cmd
      data PassSeatmassgHeat7Cmd: type=PassSeatmassgHeat7Cmd
    PassSeatmassgHeat8Cmd
      data PassSeatmassgHeat8Cmd: type=PassSeatmassgHeat8Cmd
    PassSeatmassgHeat9Cmd
      data PassSeatmassgHeat9Cmd: type=PassSeatmassgHeat9Cmd
    PassSeatmassgHeatCSts
      data PassSeatmassgHeatCSts: type=PassSeatmassgHeatCSts
    PassSeatmassgValve10Cmd
      data PassSeatmassgValve10Cmd: type=PassSeatmassgValve10Cmd
    PassSeatmassgValve11Cmd
      data PassSeatmassgValve11Cmd: type=PassSeatmassgValve11Cmd
    PassSeatmassgValve12Cmd
      data PassSeatmassgValve12Cmd: type=PassSeatmassgValve12Cmd
    PassSeatmassgValve1Cmd
      data PassSeatmassgValve1Cmd: type=PassSeatmassgValve1Cmd
    PassSeatmassgValve2Cmd
      data PassSeatmassgValve2Cmd: type=PassSeatmassgValve2Cmd
    PassSeatmassgValve3Cmd
      data PassSeatmassgValve3Cmd: type=PassSeatmassgValve3Cmd
    PassSeatmassgValve4Cmd
      data PassSeatmassgValve4Cmd: type=PassSeatmassgValve4Cmd
    PassSeatmassgValve5Cmd
      data PassSeatmassgValve5Cmd: type=PassSeatmassgValve5Cmd
    PassSeatmassgValve6Cmd
      data PassSeatmassgValve6Cmd: type=PassSeatmassgValve6Cmd
    PassSeatmassgValve7Cmd
      data PassSeatmassgValve7Cmd: type=PassSeatmassgValve7Cmd
    PassSeatmassgValve8Cmd
      data PassSeatmassgValve8Cmd: type=PassSeatmassgValve8Cmd
    PassSeatmassgValve9Cmd
      data PassSeatmassgValve9Cmd: type=PassSeatmassgValve9Cmd
    PassSeatmassgValveSts
      data PassSeatmassgValveSts: type=PassSeatmassgValveSts
    PassSystemFailr
      data PassSystemFailr: type=PassSystemFailr
    Sec
      data Sec: type=Sec
    VC_Data_5E0_CRC
      data VC_Data_5E0_CRC: type=VC_Data_5E0_CRC
    VC_Data_5E0_MsgCntr
      data VC_Data_5E0_MsgCntr: type=VC_Data_5E0_MsgCntr
    VC_Data_5E0_Payload
      data VC_Data_5E0_Payload: type=VC_Data_5E0_Payload
    VehModeDef
      data VehModeDef: type=VehModeDef
    VehOdometer
      data VehOdometer: type=VehOdometer
    VehSpdSts_Rdnt1
      data VehSpdSts_Rdnt1: type=VehSpdSts_Rdnt1
    VehSpd_Rdnt1
      data VehSpd_Rdnt1: type=VehSpd_Rdnt1
    VehStateDetailed
      data VehStateDetailed: type=VehStateDetailed
    VehStateDetailed_SrvSts
      data VehStateDetailed_SrvSts: type=VehStateDetailed_SrvSts
    Yr
      data Yr: type=Yr
    ZONE_13C_CRC
      data ZONE_13C_CRC: type=ZONE_13C_CRC
    ZONE_13C_MsgCntr
      data ZONE_13C_MsgCntr: type=ZONE_13C_MsgCntr
package /BSW/DataTypeMappingSets
  data type mapping set DataTypeMappingSet
    data-type-maps:
      application-data-type=BattVolt_LBMR, implementation-data-type=BattVolt_LBMR_IDT
      application-data-type=Day, implementation-data-type=Day_IDT
      application-data-type=DrvHeat1Sts, implementation-data-type=DrvHeat1Sts_IDT
      application-data-type=DrvHeat1_pct, implementation-data-type=DrvHeat1_pct_IDT
      application-data-type=DrvHeat2Sts, implementation-data-type=DrvHeat2Sts_IDT
      application-data-type=DrvHeat2_pct, implementation-data-type=DrvHeat2_pct_IDT
      application-data-type=DrvHeat3Sts, implementation-data-type=DrvHeat3Sts_IDT
      application-data-type=DrvHeat3_pct, implementation-data-type=DrvHeat3_pct_IDT
      application-data-type=DrvHeat4Sts, implementation-data-type=DrvHeat4Sts_IDT
      application-data-type=DrvHeat4_pct, implementation-data-type=DrvHeat4_pct_IDT
      application-data-type=DrvHeat5ErrSts, implementation-data-type=DrvHeat5ErrSts_IDT
      application-data-type=DrvHeat5Sts, implementation-data-type=DrvHeat5Sts_IDT
      application-data-type=DrvHeat5_pct, implementation-data-type=DrvHeat5_pct_IDT
      application-data-type=DrvHeat6Sts, implementation-data-type=DrvHeat6Sts_IDT
      application-data-type=DrvHeat6_pct, implementation-data-type=DrvHeat6_pct_IDT
      application-data-type=DrvKneadingMassgLvlCmd10, implementation-data-type=DrvKneadingMassgLvlCmd10_IDT
      application-data-type=DrvKneadingMassgLvlCmd{5..9}, implementation-data-type=DrvKneadingMassgLvlCmd{5..9}_IDT
      application-data-type=DrvKneadingMassgSkillsCmd10, implementation-data-type=DrvKneadingMassgSkillsCmd10_IDT
      application-data-type=DrvKneadingMassgSkillsCmd{5..9}, implementation-data-type=DrvKneadingMassgSkillsCmd{5..9}_IDT
      application-data-type=DrvKneadingMassgSkillsSts10, implementation-data-type=DrvKneadingMassgSkillsSts10_IDT
      application-data-type=DrvKneadingMassgSkillsSts{5..9}, implementation-data-type=DrvKneadingMassgSkillsSts{5..9}_IDT
      application-data-type=DrvKneadingMassgTime10, implementation-data-type=DrvKneadingMassgTime10_IDT
      application-data-type=DrvKneadingMassgTime{5..9}, implementation-data-type=DrvKneadingMassgTime{5..9}_IDT
      application-data-type=DrvKneadingMassgTimesCmd10, implementation-data-type=DrvKneadingMassgTimesCmd10_IDT
      application-data-type=DrvKneadingMassgTimesCmd{5..9}, implementation-data-type=DrvKneadingMassgTimesCmd{5..9}_IDT
      application-data-type=DrvKneadingMassglvlSts10, implementation-data-type=DrvKneadingMassglvlSts10_IDT
      application-data-type=DrvKneadingMassglvlSts{5..9}, implementation-data-type=DrvKneadingMassglvlSts{5..9}_IDT
      application-data-type=DrvLumControlSts, implementation-data-type=DrvLumControlSts_IDT
      application-data-type=DrvLumSwitchSts, implementation-data-type=DrvLumSwitchSts_IDT
      application-data-type=DrvLumbarBottomWorkSts, implementation-data-type=DrvLumbarBottomWorkSts_IDT
      application-data-type=DrvLumbarMidWorkSts, implementation-data-type=DrvLumbarMidWorkSts_IDT
      application-data-type=DrvLumbarTopWorkSts, implementation-data-type=DrvLumbarTopWorkSts_IDT
      application-data-type=DrvMassSwitchSts, implementation-data-type=DrvMassSwitchSts_IDT
      application-data-type=DrvMassageHeatNTC1, implementation-data-type=DrvMassageHeatNTC1_IDT
      application-data-type=DrvMassageHeatNTC{10..12}, implementation-data-type=DrvMassageHeatNTC{10..12}_IDT
      application-data-type=DrvMassageHeatNTC{2..9}, implementation-data-type=DrvMassageHeatNTC{2..9}_IDT
      application-data-type=DrvPumpCmd, implementation-data-type=DrvPumpCmd_IDT
      application-data-type=DrvPumpSts, implementation-data-type=DrvPumpSts_IDT
      application-data-type=DrvSeatBlosterValueSts, implementation-data-type=DrvSeatBlosterValueSts_IDT
      application-data-type=DrvSeatBolsterValueBLCmd, implementation-data-type=DrvSeatBolsterValueBLCmd_IDT
      application-data-type=DrvSeatBolsterValueBLPos, implementation-data-type=DrvSeatBolsterValueBLPos_IDT
      application-data-type=DrvSeatBolsterValueBRCmd, implementation-data-type=DrvSeatBolsterValueBRCmd_IDT
      application-data-type=DrvSeatBolsterValueBRPos, implementation-data-type=DrvSeatBolsterValueBRPos_IDT
      application-data-type=DrvSeatCushionValue1Cmd, implementation-data-type=DrvSeatCushionValue1Cmd_IDT
      application-data-type=DrvSeatCushionValue1Pos, implementation-data-type=DrvSeatCushionValue1Pos_IDT
      application-data-type=DrvSeatCushionValue2Cmd, implementation-data-type=DrvSeatCushionValue2Cmd_IDT
      application-data-type=DrvSeatCushionValue2Pos, implementation-data-type=DrvSeatCushionValue2Pos_IDT
      application-data-type=DrvSeatCushionValue3Cmd, implementation-data-type=DrvSeatCushionValue3Cmd_IDT
      application-data-type=DrvSeatCushionValue3Pos, implementation-data-type=DrvSeatCushionValue3Pos_IDT
      application-data-type=DrvSeatCushionValue4Cmd, implementation-data-type=DrvSeatCushionValue4Cmd_IDT
      application-data-type=DrvSeatCushionValue4Pos, implementation-data-type=DrvSeatCushionValue4Pos_IDT
      application-data-type=DrvSeatCushionValue5Cmd, implementation-data-type=DrvSeatCushionValue5Cmd_IDT
      application-data-type=DrvSeatCushionValue5Pos, implementation-data-type=DrvSeatCushionValue5Pos_IDT
      application-data-type=DrvSeatCushionValue6Cmd, implementation-data-type=DrvSeatCushionValue6Cmd_IDT
      application-data-type=DrvSeatCushionValue6Pos, implementation-data-type=DrvSeatCushionValue6Pos_IDT
      application-data-type=DrvSeatCushionValueSts, implementation-data-type=DrvSeatCushionValueSts_IDT
      application-data-type=DrvSeatLumbarBottomPos, implementation-data-type=DrvSeatLumbarBottomPos_IDT
      application-data-type=DrvSeatLumbarBottomValue3Cmd, implementation-data-type=DrvSeatLumbarBottomValue3Cmd_IDT
      application-data-type=DrvSeatLumbarMidPos, implementation-data-type=DrvSeatLumbarMidPos_IDT
      application-data-type=DrvSeatLumbarMidValue2Cmd, implementation-data-type=DrvSeatLumbarMidValue2Cmd_IDT
      application-data-type=DrvSeatLumbarTopPos, implementation-data-type=DrvSeatLumbarTopPos_IDT
      application-data-type=DrvSeatLumbarTopValue1Cmd, implementation-data-type=DrvSeatLumbarTopValue1Cmd_IDT
      application-data-type=DrvSeatLumbarValueSts, implementation-data-type=DrvSeatLumbarValueSts_IDT
      application-data-type=DrvSeatMassFailr, implementation-data-type=DrvSeatMassFailr_IDT
      application-data-type=DrvSeatUpperValueLCmd, implementation-data-type=DrvSeatUpperValueLCmd_IDT
      application-data-type=DrvSeatUpperValueLPos, implementation-data-type=DrvSeatUpperValueLPos_IDT
      application-data-type=DrvSeatUpperValueMCmd, implementation-data-type=DrvSeatUpperValueMCmd_IDT
      application-data-type=DrvSeatUpperValueMPos, implementation-data-type=DrvSeatUpperValueMPos_IDT
      application-data-type=DrvSeatUpperValueRCmd, implementation-data-type=DrvSeatUpperValueRCmd_IDT
      application-data-type=DrvSeatUpperValueRPos, implementation-data-type=DrvSeatUpperValueRPos_IDT
      application-data-type=DrvSeatUpperValueSts, implementation-data-type=DrvSeatUpperValueSts_IDT
      application-data-type=DrvSeatmassgHeat{10..12}Cmd, implementation-data-type=DrvSeatmassgHeat{10..12}Cmd_IDT
      application-data-type=DrvSeatmassgHeat{1..9}Cmd, implementation-data-type=DrvSeatmassgHeat{1..9}Cmd_IDT
      application-data-type=DrvSeatmassgHeatCSts, implementation-data-type=DrvSeatmassgHeatCSts_IDT
      application-data-type=DrvSeatmassgValve{10..12}Cmd, implementation-data-type=DrvSeatmassgValve{10..12}Cmd_IDT
      application-data-type=DrvSeatmassgValve{1..9}Cmd, implementation-data-type=DrvSeatmassgValve{1..9}Cmd_IDT
      application-data-type=DrvSeatmassgValveSts, implementation-data-type=DrvSeatmassgValveSts_IDT
      application-data-type=DrvState, implementation-data-type=DrvState_IDT
      application-data-type=DrvState_SrvSts, implementation-data-type=DrvState_SrvSts_IDT
      application-data-type=DrvSystemFailr, implementation-data-type=DrvSystemFailr_IDT
      application-data-type=Hr, implementation-data-type=Hr_IDT
      application-data-type=MSec, implementation-data-type=MSec_IDT
      application-data-type=Min, implementation-data-type=Min_IDT
      application-data-type=Mth, implementation-data-type=Mth_IDT
      application-data-type=OperatorState, implementation-data-type=OperatorState_IDT
      application-data-type=OperatorState_SrvSts, implementation-data-type=OperatorState_SrvSts_IDT
      application-data-type=PNC{10..19}_Sts, implementation-data-type=PNC{10..19}_Sts_IDT
      application-data-type=PNC1_Sts, implementation-data-type=PNC1_Sts_IDT
      application-data-type=PNC{20..29}_Sts, implementation-data-type=PNC{20..29}_Sts_IDT
      application-data-type=PNC2_Sts, implementation-data-type=PNC2_Sts_IDT
      application-data-type=PNC{30..39}_Sts, implementation-data-type=PNC{30..39}_Sts_IDT
      application-data-type=PNC3_Sts, implementation-data-type=PNC3_Sts_IDT
      application-data-type=PNC{40..48}_Sts, implementation-data-type=PNC{40..48}_Sts_IDT
      application-data-type=PNC{4..9}_Sts, implementation-data-type=PNC{4..9}_Sts_IDT
      application-data-type=PNC_DFT, implementation-data-type=PNC_DFT_IDT
      application-data-type=PassHeat1Sts, implementation-data-type=PassHeat1Sts_IDT
      application-data-type=PassHeat1_pct, implementation-data-type=PassHeat1_pct_IDT
      application-data-type=PassHeat2Sts, implementation-data-type=PassHeat2Sts_IDT
      application-data-type=PassHeat2_pct, implementation-data-type=PassHeat2_pct_IDT
      application-data-type=PassHeat3Sts, implementation-data-type=PassHeat3Sts_IDT
      application-data-type=PassHeat3_pct, implementation-data-type=PassHeat3_pct_IDT
      application-data-type=PassHeat4Sts, implementation-data-type=PassHeat4Sts_IDT
      application-data-type=PassHeat4_pct, implementation-data-type=PassHeat4_pct_IDT
      application-data-type=PassHeat5ErrSts, implementation-data-type=PassHeat5ErrSts_IDT
      application-data-type=PassHeat5Sts, implementation-data-type=PassHeat5Sts_IDT
      application-data-type=PassHeat5_pct, implementation-data-type=PassHeat5_pct_IDT
      application-data-type=PassHeat6Sts, implementation-data-type=PassHeat6Sts_IDT
      application-data-type=PassHeat6_pct, implementation-data-type=PassHeat6_pct_IDT
      application-data-type=PassKneadingMassgLvlCmd10, implementation-data-type=PassKneadingMassgLvlCmd10_IDT
      application-data-type=PassKneadingMassgLvlCmd{5..9}, implementation-data-type=PassKneadingMassgLvlCmd{5..9}_IDT
      application-data-type=PassKneadingMassgLvlSts10, implementation-data-type=PassKneadingMassgLvlSts10_IDT
      application-data-type=PassKneadingMassgLvlSts{5..9}, implementation-data-type=PassKneadingMassgLvlSts{5..9}_IDT
      application-data-type=PassKneadingMassgSkillsCmd10, implementation-data-type=PassKneadingMassgSkillsCmd10_IDT
      application-data-type=PassKneadingMassgSkillsCmd{5..9}, implementation-data-type=PassKneadingMassgSkillsCmd{5..9}_IDT
      application-data-type=PassKneadingMassgSkillsSts10, implementation-data-type=PassKneadingMassgSkillsSts10_IDT
      application-data-type=PassKneadingMassgSkillsSts{5..9}, implementation-data-type=PassKneadingMassgSkillsSts{5..9}_IDT
      application-data-type=PassKneadingMassgTime10, implementation-data-type=PassKneadingMassgTime10_IDT
      application-data-type=PassKneadingMassgTime{5..9}, implementation-data-type=PassKneadingMassgTime{5..9}_IDT
      application-data-type=PassKneadingMassgTimesCmd10, implementation-data-type=PassKneadingMassgTimesCmd10_IDT
      application-data-type=PassKneadingMassgTimesCmd{5..9}, implementation-data-type=PassKneadingMassgTimesCmd{5..9}_IDT
      application-data-type=PassLumControlSts, implementation-data-type=PassLumControlSts_IDT
      application-data-type=PassLumSwitchSts, implementation-data-type=PassLumSwitchSts_IDT
      application-data-type=PassLumbarBottomWorkSts, implementation-data-type=PassLumbarBottomWorkSts_IDT
      application-data-type=PassLumbarMidWorkSts, implementation-data-type=PassLumbarMidWorkSts_IDT
      application-data-type=PassLumbarTopWorkSts, implementation-data-type=PassLumbarTopWorkSts_IDT
      application-data-type=PassMassSwitchSts, implementation-data-type=PassMassSwitchSts_IDT
      application-data-type=PassMassageHeatNTC1, implementation-data-type=PassMassageHeatNTC1_IDT
      application-data-type=PassMassageHeatNTC{10..12}, implementation-data-type=PassMassageHeatNTC{10..12}_IDT
      application-data-type=PassMassageHeatNTC{2..9}, implementation-data-type=PassMassageHeatNTC{2..9}_IDT
      application-data-type=PassPumpCmd, implementation-data-type=PassPumpCmd_IDT
      application-data-type=PassPumpSts, implementation-data-type=PassPumpSts_IDT
      application-data-type=PassSeatBlosterValueSts, implementation-data-type=PassSeatBlosterValueSts_IDT
      application-data-type=PassSeatBolsterValueBLCmd, implementation-data-type=PassSeatBolsterValueBLCmd_IDT
      application-data-type=PassSeatBolsterValueBLPos, implementation-data-type=PassSeatBolsterValueBLPos_IDT
      application-data-type=PassSeatBolsterValueBRCmd, implementation-data-type=PassSeatBolsterValueBRCmd_IDT
      application-data-type=PassSeatBolsterValueBRPos, implementation-data-type=PassSeatBolsterValueBRPos_IDT
      application-data-type=PassSeatCushionValue1Cmd, implementation-data-type=PassSeatCushionValue1Cmd_IDT
      application-data-type=PassSeatCushionValue1Pos, implementation-data-type=PassSeatCushionValue1Pos_IDT
      application-data-type=PassSeatCushionValue2Cmd, implementation-data-type=PassSeatCushionValue2Cmd_IDT
      application-data-type=PassSeatCushionValue2Pos, implementation-data-type=PassSeatCushionValue2Pos_IDT
      application-data-type=PassSeatCushionValue3Cmd, implementation-data-type=PassSeatCushionValue3Cmd_IDT
      application-data-type=PassSeatCushionValue3Pos, implementation-data-type=PassSeatCushionValue3Pos_IDT
      application-data-type=PassSeatCushionValue4Cmd, implementation-data-type=PassSeatCushionValue4Cmd_IDT
      application-data-type=PassSeatCushionValue4Pos, implementation-data-type=PassSeatCushionValue4Pos_IDT
      application-data-type=PassSeatCushionValue5Cmd, implementation-data-type=PassSeatCushionValue5Cmd_IDT
      application-data-type=PassSeatCushionValue5Pos, implementation-data-type=PassSeatCushionValue5Pos_IDT
      application-data-type=PassSeatCushionValue6Cmd, implementation-data-type=PassSeatCushionValue6Cmd_IDT
      application-data-type=PassSeatCushionValue6Pos, implementation-data-type=PassSeatCushionValue6Pos_IDT
      application-data-type=PassSeatCushionValueSts, implementation-data-type=PassSeatCushionValueSts_IDT
      application-data-type=PassSeatLumbarBottomPos, implementation-data-type=PassSeatLumbarBottomPos_IDT
      application-data-type=PassSeatLumbarBottomValue3Cmd, implementation-data-type=PassSeatLumbarBottomValue3Cmd_IDT
      application-data-type=PassSeatLumbarMidPos, implementation-data-type=PassSeatLumbarMidPos_IDT
      application-data-type=PassSeatLumbarMidValue2Cmd, implementation-data-type=PassSeatLumbarMidValue2Cmd_IDT
      application-data-type=PassSeatLumbarTopPos, implementation-data-type=PassSeatLumbarTopPos_IDT
      application-data-type=PassSeatLumbarTopValue1Cmd, implementation-data-type=PassSeatLumbarTopValue1Cmd_IDT
      application-data-type=PassSeatLumbarValueSts, implementation-data-type=PassSeatLumbarValueSts_IDT
      application-data-type=PassSeatMassFailr, implementation-data-type=PassSeatMassFailr_IDT
      application-data-type=PassSeatUpperValueLCmd, implementation-data-type=PassSeatUpperValueLCmd_IDT
      application-data-type=PassSeatUpperValueLPos, implementation-data-type=PassSeatUpperValueLPos_IDT
      application-data-type=PassSeatUpperValueMCmd, implementation-data-type=PassSeatUpperValueMCmd_IDT
      application-data-type=PassSeatUpperValueMPos, implementation-data-type=PassSeatUpperValueMPos_IDT
      application-data-type=PassSeatUpperValueRCmd, implementation-data-type=PassSeatUpperValueRCmd_IDT
      application-data-type=PassSeatUpperValueRPos, implementation-data-type=PassSeatUpperValueRPos_IDT
      application-data-type=PassSeatUpperValueSts, implementation-data-type=PassSeatUpperValueSts_IDT
      application-data-type=PassSeatmassgHeat{10..12}Cmd, implementation-data-type=PassSeatmassgHeat{10..12}Cmd_IDT
      application-data-type=PassSeatmassgHeat{1..9}Cmd, implementation-data-type=PassSeatmassgHeat{1..9}Cmd_IDT
      application-data-type=PassSeatmassgHeatCSts, implementation-data-type=PassSeatmassgHeatCSts_IDT
      application-data-type=PassSeatmassgValve{10..12}Cmd, implementation-data-type=PassSeatmassgValve{10..12}Cmd_IDT
      application-data-type=PassSeatmassgValve{1..9}Cmd, implementation-data-type=PassSeatmassgValve{1..9}Cmd_IDT
      application-data-type=PassSeatmassgValveSts, implementation-data-type=PassSeatmassgValveSts_IDT
      application-data-type=PassSystemFailr, implementation-data-type=PassSystemFailr_IDT
      application-data-type=Sec, implementation-data-type=Sec_IDT
      application-data-type=VC_Data_5E0_CRC, implementation-data-type=VC_Data_5E0_CRC_IDT
      application-data-type=VC_Data_5E0_MsgCntr, implementation-data-type=VC_Data_5E0_MsgCntr_IDT
      application-data-type=VC_Data_5E0_Payload, implementation-data-type=VC_Data_5E0_Payload_IDT
      application-data-type=VehModeDef, implementation-data-type=VehModeDef_IDT
      application-data-type=VehOdometer, implementation-data-type=VehOdometer_IDT
      application-data-type=VehSpdSts_Rdnt1, implementation-data-type=VehSpdSts_Rdnt1_IDT
      application-data-type=VehSpd_Rdnt1, implementation-data-type=VehSpd_Rdnt1_IDT
      application-data-type=VehStateDetailed, implementation-data-type=VehStateDetailed_IDT
      application-data-type=VehStateDetailed_SrvSts, implementation-data-type=VehStateDetailed_SrvSts_IDT
      application-data-type=Yr, implementation-data-type=Yr_IDT
      application-data-type=ZONE_13C_CRC, implementation-data-type=ZONE_13C_CRC_IDT
      application-data-type=ZONE_13C_MsgCntr, implementation-data-type=ZONE_13C_MsgCntr_IDT
      application-data-type=uint16, implementation-data-type=uint16
      application-data-type=uint32, implementation-data-type=uint32
      application-data-type=uint8, implementation-data-type=uint8
package /BSW/SWCs
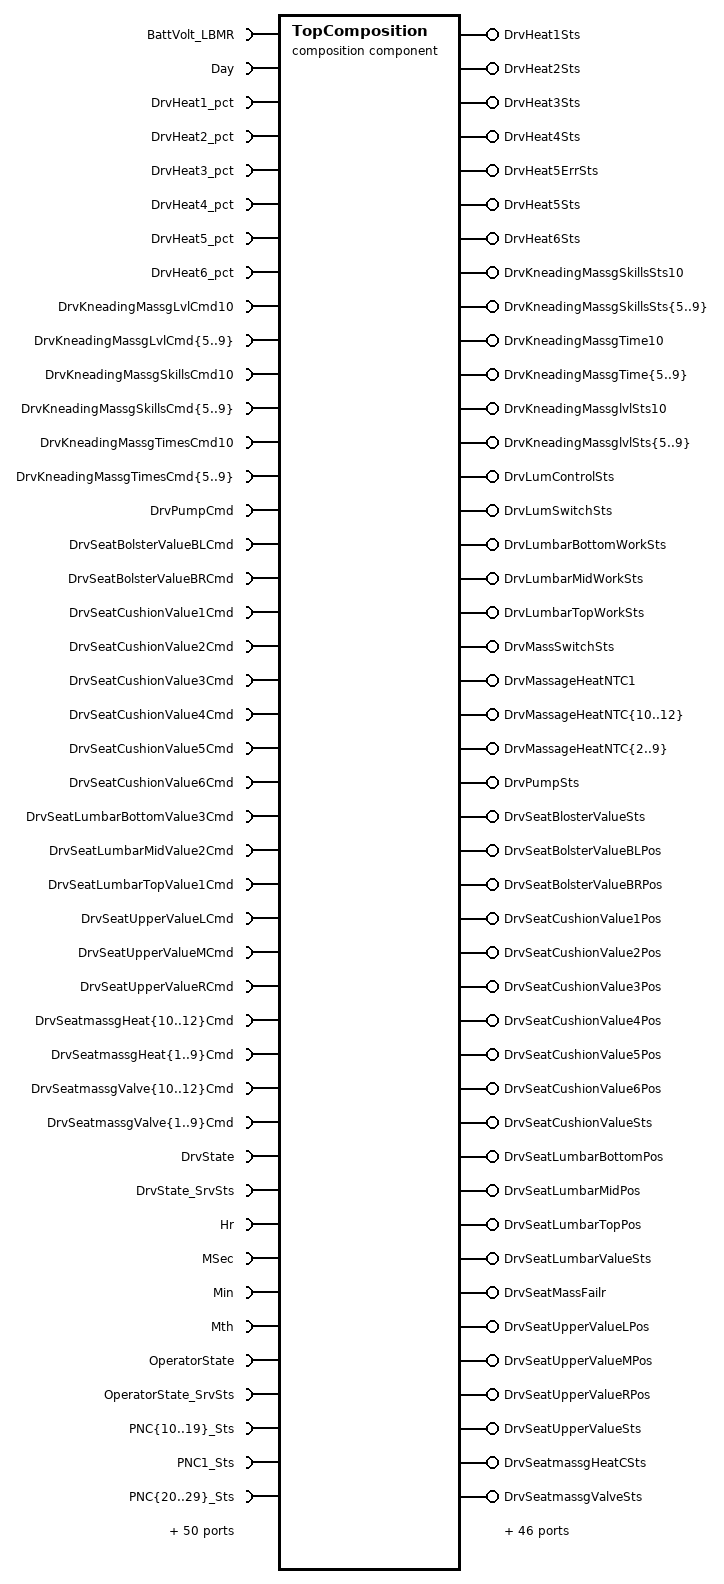
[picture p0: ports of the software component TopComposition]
  composition sw component type TopComposition
    require port BattVolt_LBMR: nonqueued-receiver-com-spec{data-element=BattVolt_LBMR, init-value=0}, required-interface=BattVolt_LBMR
    require port Day: nonqueued-receiver-com-spec{data-element=Day, alive-timeout=0.5, init-value=0}, required-interface=Day
    provide port DrvHeat1Sts: nonqueued-sender-com-spec{data-element=DrvHeat1Sts, init-value=0}, provided-interface=DrvHeat1Sts
    require port DrvHeat1_pct: nonqueued-receiver-com-spec{data-element=DrvHeat1_pct, init-value=0}, required-interface=DrvHeat1_pct
    provide port DrvHeat2Sts: nonqueued-sender-com-spec{data-element=DrvHeat2Sts, init-value=0}, provided-interface=DrvHeat2Sts
    require port DrvHeat2_pct: nonqueued-receiver-com-spec{data-element=DrvHeat2_pct, init-value=0}, required-interface=DrvHeat2_pct
    provide port DrvHeat3Sts: nonqueued-sender-com-spec{data-element=DrvHeat3Sts, init-value=0}, provided-interface=DrvHeat3Sts
    require port DrvHeat3_pct: nonqueued-receiver-com-spec{data-element=DrvHeat3_pct, init-value=0}, required-interface=DrvHeat3_pct
    provide port DrvHeat4Sts: nonqueued-sender-com-spec{data-element=DrvHeat4Sts, init-value=0}, provided-interface=DrvHeat4Sts
    require port DrvHeat4_pct: nonqueued-receiver-com-spec{data-element=DrvHeat4_pct, init-value=0}, required-interface=DrvHeat4_pct
    provide port DrvHeat5ErrSts: nonqueued-sender-com-spec{data-element=DrvHeat5ErrSts, init-value=0}, provided-interface=DrvHeat5ErrSts
    provide port DrvHeat5Sts: nonqueued-sender-com-spec{data-element=DrvHeat5Sts, init-value=0}, provided-interface=DrvHeat5Sts
    require port DrvHeat5_pct: nonqueued-receiver-com-spec{data-element=DrvHeat5_pct, init-value=0}, required-interface=DrvHeat5_pct
    provide port DrvHeat6Sts: nonqueued-sender-com-spec{data-element=DrvHeat6Sts, init-value=0}, provided-interface=DrvHeat6Sts
    13 x require port:
      DrvHeat6_pct: nonqueued-receiver-com-spec{data-element=DrvHeat6_pct, init-value=0}, required-interface=DrvHeat6_pct
      DrvKneadingMassgLvlCmd10: nonqueued-receiver-com-spec{data-element=DrvKneadingMassgLvlCmd10, init-value=0}, required-interface=DrvKneadingMassgLvlCmd10
      DrvKneadingMassgLvlCmd{5..9}: nonqueued-receiver-com-spec{data-element=DrvKneadingMassgLvlCmd{5..9}, init-value=0}, required-interface=DrvKneadingMassgLvlCmd{5..9}
      DrvKneadingMassgSkillsCmd10: nonqueued-receiver-com-spec{data-element=DrvKneadingMassgSkillsCmd10, init-value=0}, required-interface=DrvKneadingMassgSkillsCmd10
      DrvKneadingMassgSkillsCmd{5..9}: nonqueued-receiver-com-spec{data-element=DrvKneadingMassgSkillsCmd{5..9}, init-value=0}, required-interface=DrvKneadingMassgSkillsCmd{5..9}
    12 x provide port:
      DrvKneadingMassgSkillsSts10: nonqueued-sender-com-spec{data-element=DrvKneadingMassgSkillsSts10, init-value=0}, provided-interface=DrvKneadingMassgSkillsSts10
      DrvKneadingMassgSkillsSts{5..9}: nonqueued-sender-com-spec{data-element=DrvKneadingMassgSkillsSts{5..9}, init-value=0}, provided-interface=DrvKneadingMassgSkillsSts{5..9}
      DrvKneadingMassgTime10: nonqueued-sender-com-spec{data-element=DrvKneadingMassgTime10, init-value=0}, provided-interface=DrvKneadingMassgTime10
      DrvKneadingMassgTime{5..9}: nonqueued-sender-com-spec{data-element=DrvKneadingMassgTime{5..9}, init-value=0}, provided-interface=DrvKneadingMassgTime{5..9}
    6 x require port:
      DrvKneadingMassgTimesCmd10: nonqueued-receiver-com-spec{data-element=DrvKneadingMassgTimesCmd10, init-value=0}, required-interface=DrvKneadingMassgTimesCmd10
      DrvKneadingMassgTimesCmd{5..9}: nonqueued-receiver-com-spec{data-element=DrvKneadingMassgTimesCmd{5..9}, init-value=0}, required-interface=DrvKneadingMassgTimesCmd{5..9}
    24 x provide port:
      DrvKneadingMassglvlSts10: nonqueued-sender-com-spec{data-element=DrvKneadingMassglvlSts10, init-value=0}, provided-interface=DrvKneadingMassglvlSts10
      DrvKneadingMassglvlSts{5..9}: nonqueued-sender-com-spec{data-element=DrvKneadingMassglvlSts{5..9}, init-value=0}, provided-interface=DrvKneadingMassglvlSts{5..9}
      DrvLumControlSts: nonqueued-sender-com-spec{data-element=DrvLumControlSts, init-value=0}, provided-interface=DrvLumControlSts
      DrvLumSwitchSts: nonqueued-sender-com-spec{data-element=DrvLumSwitchSts, init-value=0}, provided-interface=DrvLumSwitchSts
      DrvLumbarBottomWorkSts: nonqueued-sender-com-spec{data-element=DrvLumbarBottomWorkSts, init-value=0}, provided-interface=DrvLumbarBottomWorkSts
      DrvLumbarMidWorkSts: nonqueued-sender-com-spec{data-element=DrvLumbarMidWorkSts, init-value=0}, provided-interface=DrvLumbarMidWorkSts
      DrvLumbarTopWorkSts: nonqueued-sender-com-spec{data-element=DrvLumbarTopWorkSts, init-value=0}, provided-interface=DrvLumbarTopWorkSts
      DrvMassSwitchSts: nonqueued-sender-com-spec{data-element=DrvMassSwitchSts, init-value=0}, provided-interface=DrvMassSwitchSts
      DrvMassageHeatNTC1: nonqueued-sender-com-spec{data-element=DrvMassageHeatNTC1, init-value=0}, provided-interface=DrvMassageHeatNTC1
      DrvMassageHeatNTC{10..12}: nonqueued-sender-com-spec{data-element=DrvMassageHeatNTC{10..12}, init-value=0}, provided-interface=DrvMassageHeatNTC{10..12}
      DrvMassageHeatNTC{2..9}: nonqueued-sender-com-spec{data-element=DrvMassageHeatNTC{2..9}, init-value=0}, provided-interface=DrvMassageHeatNTC{2..9}
    require port DrvPumpCmd: nonqueued-receiver-com-spec{data-element=DrvPumpCmd, alive-timeout=0.5, init-value=0}, required-interface=DrvPumpCmd
    provide port DrvPumpSts: nonqueued-sender-com-spec{data-element=DrvPumpSts, init-value=0}, provided-interface=DrvPumpSts
    provide port DrvSeatBlosterValueSts: nonqueued-sender-com-spec{data-element=DrvSeatBlosterValueSts, init-value=0}, provided-interface=DrvSeatBlosterValueSts
    require port DrvSeatBolsterValueBLCmd: nonqueued-receiver-com-spec{data-element=DrvSeatBolsterValueBLCmd, alive-timeout=0.5, init-value=0}, required-interface=DrvSeatBolsterValueBLCmd
    provide port DrvSeatBolsterValueBLPos: nonqueued-sender-com-spec{data-element=DrvSeatBolsterValueBLPos, init-value=0}, provided-interface=DrvSeatBolsterValueBLPos
    require port DrvSeatBolsterValueBRCmd: nonqueued-receiver-com-spec{data-element=DrvSeatBolsterValueBRCmd, alive-timeout=0.5, init-value=0}, required-interface=DrvSeatBolsterValueBRCmd
    provide port DrvSeatBolsterValueBRPos: nonqueued-sender-com-spec{data-element=DrvSeatBolsterValueBRPos, init-value=0}, provided-interface=DrvSeatBolsterValueBRPos
    require port DrvSeatCushionValue1Cmd: nonqueued-receiver-com-spec{data-element=DrvSeatCushionValue1Cmd, alive-timeout=0.5, init-value=0}, required-interface=DrvSeatCushionValue1Cmd
    provide port DrvSeatCushionValue1Pos: nonqueued-sender-com-spec{data-element=DrvSeatCushionValue1Pos, init-value=0}, provided-interface=DrvSeatCushionValue1Pos
    require port DrvSeatCushionValue2Cmd: nonqueued-receiver-com-spec{data-element=DrvSeatCushionValue2Cmd, alive-timeout=0.5, init-value=0}, required-interface=DrvSeatCushionValue2Cmd
    provide port DrvSeatCushionValue2Pos: nonqueued-sender-com-spec{data-element=DrvSeatCushionValue2Pos, init-value=0}, provided-interface=DrvSeatCushionValue2Pos
    require port DrvSeatCushionValue3Cmd: nonqueued-receiver-com-spec{data-element=DrvSeatCushionValue3Cmd, alive-timeout=0.5, init-value=0}, required-interface=DrvSeatCushionValue3Cmd
    provide port DrvSeatCushionValue3Pos: nonqueued-sender-com-spec{data-element=DrvSeatCushionValue3Pos, init-value=0}, provided-interface=DrvSeatCushionValue3Pos
    require port DrvSeatCushionValue4Cmd: nonqueued-receiver-com-spec{data-element=DrvSeatCushionValue4Cmd, alive-timeout=0.5, init-value=0}, required-interface=DrvSeatCushionValue4Cmd
    provide port DrvSeatCushionValue4Pos: nonqueued-sender-com-spec{data-element=DrvSeatCushionValue4Pos, init-value=0}, provided-interface=DrvSeatCushionValue4Pos
    require port DrvSeatCushionValue5Cmd: nonqueued-receiver-com-spec{data-element=DrvSeatCushionValue5Cmd, alive-timeout=0.5, init-value=0}, required-interface=DrvSeatCushionValue5Cmd
    provide port DrvSeatCushionValue5Pos: nonqueued-sender-com-spec{data-element=DrvSeatCushionValue5Pos, init-value=0}, provided-interface=DrvSeatCushionValue5Pos
    require port DrvSeatCushionValue6Cmd: nonqueued-receiver-com-spec{data-element=DrvSeatCushionValue6Cmd, alive-timeout=0.5, init-value=0}, required-interface=DrvSeatCushionValue6Cmd
    provide port DrvSeatCushionValue6Pos: nonqueued-sender-com-spec{data-element=DrvSeatCushionValue6Pos, init-value=0}, provided-interface=DrvSeatCushionValue6Pos
    provide port DrvSeatCushionValueSts: nonqueued-sender-com-spec{data-element=DrvSeatCushionValueSts, init-value=0}, provided-interface=DrvSeatCushionValueSts
    provide port DrvSeatLumbarBottomPos: nonqueued-sender-com-spec{data-element=DrvSeatLumbarBottomPos, init-value=0}, provided-interface=DrvSeatLumbarBottomPos
    require port DrvSeatLumbarBottomValue3Cmd: nonqueued-receiver-com-spec{data-element=DrvSeatLumbarBottomValue3Cmd, alive-timeout=0.5, init-value=0}, required-interface=DrvSeatLumbarBottomValue3Cmd
    provide port DrvSeatLumbarMidPos: nonqueued-sender-com-spec{data-element=DrvSeatLumbarMidPos, init-value=0}, provided-interface=DrvSeatLumbarMidPos
    require port DrvSeatLumbarMidValue2Cmd: nonqueued-receiver-com-spec{data-element=DrvSeatLumbarMidValue2Cmd, alive-timeout=0.5, init-value=0}, required-interface=DrvSeatLumbarMidValue2Cmd
    provide port DrvSeatLumbarTopPos: nonqueued-sender-com-spec{data-element=DrvSeatLumbarTopPos, init-value=0}, provided-interface=DrvSeatLumbarTopPos
    require port DrvSeatLumbarTopValue1Cmd: nonqueued-receiver-com-spec{data-element=DrvSeatLumbarTopValue1Cmd, alive-timeout=0.5, init-value=0}, required-interface=DrvSeatLumbarTopValue1Cmd
    provide port DrvSeatLumbarValueSts: nonqueued-sender-com-spec{data-element=DrvSeatLumbarValueSts, init-value=0}, provided-interface=DrvSeatLumbarValueSts
    provide port DrvSeatMassFailr: nonqueued-sender-com-spec{data-element=DrvSeatMassFailr, init-value=0}, provided-interface=DrvSeatMassFailr
    require port DrvSeatUpperValueLCmd: nonqueued-receiver-com-spec{data-element=DrvSeatUpperValueLCmd, alive-timeout=0.5, init-value=0}, required-interface=DrvSeatUpperValueLCmd
    provide port DrvSeatUpperValueLPos: nonqueued-sender-com-spec{data-element=DrvSeatUpperValueLPos, init-value=0}, provided-interface=DrvSeatUpperValueLPos
    require port DrvSeatUpperValueMCmd: nonqueued-receiver-com-spec{data-element=DrvSeatUpperValueMCmd, alive-timeout=0.5, init-value=0}, required-interface=DrvSeatUpperValueMCmd
    provide port DrvSeatUpperValueMPos: nonqueued-sender-com-spec{data-element=DrvSeatUpperValueMPos, init-value=0}, provided-interface=DrvSeatUpperValueMPos
    require port DrvSeatUpperValueRCmd: nonqueued-receiver-com-spec{data-element=DrvSeatUpperValueRCmd, alive-timeout=0.5, init-value=0}, required-interface=DrvSeatUpperValueRCmd
    provide port DrvSeatUpperValueRPos: nonqueued-sender-com-spec{data-element=DrvSeatUpperValueRPos, init-value=0}, provided-interface=DrvSeatUpperValueRPos
    provide port DrvSeatUpperValueSts: nonqueued-sender-com-spec{data-element=DrvSeatUpperValueSts, init-value=0}, provided-interface=DrvSeatUpperValueSts
    12 x require port:
      DrvSeatmassgHeat{10..12}Cmd: nonqueued-receiver-com-spec{data-element=DrvSeatmassgHeat{10..12}Cmd, alive-timeout=0.5, init-value=0}, required-interface=DrvSeatmassgHeat{10..12}Cmd
      DrvSeatmassgHeat{1..9}Cmd: nonqueued-receiver-com-spec{data-element=DrvSeatmassgHeat{1..9}Cmd, alive-timeout=0.5, init-value=0}, required-interface=DrvSeatmassgHeat{1..9}Cmd
    provide port DrvSeatmassgHeatCSts: nonqueued-sender-com-spec{data-element=DrvSeatmassgHeatCSts, init-value=0}, provided-interface=DrvSeatmassgHeatCSts
    12 x require port:
      DrvSeatmassgValve{10..12}Cmd: nonqueued-receiver-com-spec{data-element=DrvSeatmassgValve{10..12}Cmd, alive-timeout=0.5, init-value=0}, required-interface=DrvSeatmassgValve{10..12}Cmd
      DrvSeatmassgValve{1..9}Cmd: nonqueued-receiver-com-spec{data-element=DrvSeatmassgValve{1..9}Cmd, alive-timeout=0.5, init-value=0}, required-interface=DrvSeatmassgValve{1..9}Cmd
    provide port DrvSeatmassgValveSts: nonqueued-sender-com-spec{data-element=DrvSeatmassgValveSts, init-value=0}, provided-interface=DrvSeatmassgValveSts
    require port DrvState: nonqueued-receiver-com-spec{data-element=DrvState, alive-timeout=0.5, init-value=0}, required-interface=DrvState
    require port DrvState_SrvSts: nonqueued-receiver-com-spec{data-element=DrvState_SrvSts, alive-timeout=0.5, init-value=0}, required-interface=DrvState_SrvSts
    provide port DrvSystemFailr: nonqueued-sender-com-spec{data-element=DrvSystemFailr, init-value=0}, provided-interface=DrvSystemFailr
    55 x require port:
      Hr: nonqueued-receiver-com-spec{data-element=Hr, alive-timeout=0.5, init-value=0}, required-interface=Hr
      MSec: nonqueued-receiver-com-spec{data-element=MSec, alive-timeout=0.5, init-value=0}, required-interface=MSec
      Min: nonqueued-receiver-com-spec{data-element=Min, alive-timeout=0.5, init-value=0}, required-interface=Min
      Mth: nonqueued-receiver-com-spec{data-element=Mth, alive-timeout=0.5, init-value=0}, required-interface=Mth
      OperatorState: nonqueued-receiver-com-spec{data-element=OperatorState, alive-timeout=0.5, init-value=0}, required-interface=OperatorState
      OperatorState_SrvSts: nonqueued-receiver-com-spec{data-element=OperatorState_SrvSts, alive-timeout=0.5, init-value=0}, required-interface=OperatorState_SrvSts
      PNC{10..19}_Sts: nonqueued-receiver-com-spec{data-element=PNC{10..19}_Sts, init-value=0}, required-interface=PNC{10..19}_Sts
      PNC1_Sts: nonqueued-receiver-com-spec{data-element=PNC1_Sts, init-value=0}, required-interface=PNC1_Sts
      PNC{20..29}_Sts: nonqueued-receiver-com-spec{data-element=PNC{20..29}_Sts, init-value=0}, required-interface=PNC{20..29}_Sts
      PNC2_Sts: nonqueued-receiver-com-spec{data-element=PNC2_Sts, init-value=0}, required-interface=PNC2_Sts
      PNC{30..39}_Sts: nonqueued-receiver-com-spec{data-element=PNC{30..39}_Sts, init-value=0}, required-interface=PNC{30..39}_Sts
      PNC3_Sts: nonqueued-receiver-com-spec{data-element=PNC3_Sts, init-value=0}, required-interface=PNC3_Sts
      PNC{40..48}_Sts: nonqueued-receiver-com-spec{data-element=PNC{40..48}_Sts, init-value=0}, required-interface=PNC{40..48}_Sts
      PNC{4..9}_Sts: nonqueued-receiver-com-spec{data-element=PNC{4..9}_Sts, init-value=0}, required-interface=PNC{4..9}_Sts
      PNC_DFT: nonqueued-receiver-com-spec{data-element=PNC_DFT, init-value=0}, required-interface=PNC_DFT
    provide port PassHeat1Sts: nonqueued-sender-com-spec{data-element=PassHeat1Sts, init-value=0}, provided-interface=PassHeat1Sts
    require port PassHeat1_pct: nonqueued-receiver-com-spec{data-element=PassHeat1_pct, init-value=0}, required-interface=PassHeat1_pct
    provide port PassHeat2Sts: nonqueued-sender-com-spec{data-element=PassHeat2Sts, init-value=0}, provided-interface=PassHeat2Sts
    require port PassHeat2_pct: nonqueued-receiver-com-spec{data-element=PassHeat2_pct, init-value=0}, required-interface=PassHeat2_pct
    provide port PassHeat3Sts: nonqueued-sender-com-spec{data-element=PassHeat3Sts, init-value=0}, provided-interface=PassHeat3Sts
    require port PassHeat3_pct: nonqueued-receiver-com-spec{data-element=PassHeat3_pct, init-value=0}, required-interface=PassHeat3_pct
    provide port PassHeat4Sts: nonqueued-sender-com-spec{data-element=PassHeat4Sts, init-value=0}, provided-interface=PassHeat4Sts
    require port PassHeat4_pct: nonqueued-receiver-com-spec{data-element=PassHeat4_pct, init-value=0}, required-interface=PassHeat4_pct
    provide port PassHeat5ErrSts: nonqueued-sender-com-spec{data-element=PassHeat5ErrSts, init-value=0}, provided-interface=PassHeat5ErrSts
    provide port PassHeat5Sts: nonqueued-sender-com-spec{data-element=PassHeat5Sts, init-value=0}, provided-interface=PassHeat5Sts
    require port PassHeat5_pct: nonqueued-receiver-com-spec{data-element=PassHeat5_pct, init-value=0}, required-interface=PassHeat5_pct
    provide port PassHeat6Sts: nonqueued-sender-com-spec{data-element=PassHeat6Sts, init-value=0}, provided-interface=PassHeat6Sts
    7 x require port:
      PassHeat6_pct: nonqueued-receiver-com-spec{data-element=PassHeat6_pct, init-value=0}, required-interface=PassHeat6_pct
      PassKneadingMassgLvlCmd10: nonqueued-receiver-com-spec{data-element=PassKneadingMassgLvlCmd10, init-value=0}, required-interface=PassKneadingMassgLvlCmd10
      PassKneadingMassgLvlCmd{5..9}: nonqueued-receiver-com-spec{data-element=PassKneadingMassgLvlCmd{5..9}, init-value=0}, required-interface=PassKneadingMassgLvlCmd{5..9}
    6 x provide port:
      PassKneadingMassgLvlSts10: nonqueued-sender-com-spec{data-element=PassKneadingMassgLvlSts10, init-value=0}, provided-interface=PassKneadingMassgLvlSts10
      PassKneadingMassgLvlSts{5..9}: nonqueued-sender-com-spec{data-element=PassKneadingMassgLvlSts{5..9}, init-value=0}, provided-interface=PassKneadingMassgLvlSts{5..9}
    6 x require port:
      PassKneadingMassgSkillsCmd10: nonqueued-receiver-com-spec{data-element=PassKneadingMassgSkillsCmd10, init-value=0}, required-interface=PassKneadingMassgSkillsCmd10
      PassKneadingMassgSkillsCmd{5..9}: nonqueued-receiver-com-spec{data-element=PassKneadingMassgSkillsCmd{5..9}, init-value=0}, required-interface=PassKneadingMassgSkillsCmd{5..9}
    12 x provide port:
      PassKneadingMassgSkillsSts10: nonqueued-sender-com-spec{data-element=PassKneadingMassgSkillsSts10, init-value=0}, provided-interface=PassKneadingMassgSkillsSts10
      PassKneadingMassgSkillsSts{5..9}: nonqueued-sender-com-spec{data-element=PassKneadingMassgSkillsSts{5..9}, init-value=0}, provided-interface=PassKneadingMassgSkillsSts{5..9}
      PassKneadingMassgTime10: nonqueued-sender-com-spec{data-element=PassKneadingMassgTime10, init-value=0}, provided-interface=PassKneadingMassgTime10
      PassKneadingMassgTime{5..9}: nonqueued-sender-com-spec{data-element=PassKneadingMassgTime{5..9}, init-value=0}, provided-interface=PassKneadingMassgTime{5..9}
    6 x require port:
      PassKneadingMassgTimesCmd10: nonqueued-receiver-com-spec{data-element=PassKneadingMassgTimesCmd10, init-value=0}, required-interface=PassKneadingMassgTimesCmd10
      PassKneadingMassgTimesCmd{5..9}: nonqueued-receiver-com-spec{data-element=PassKneadingMassgTimesCmd{5..9}, init-value=0}, required-interface=PassKneadingMassgTimesCmd{5..9}
    18 x provide port:
      PassLumControlSts: nonqueued-sender-com-spec{data-element=PassLumControlSts, init-value=0}, provided-interface=PassLumControlSts
      PassLumSwitchSts: nonqueued-sender-com-spec{data-element=PassLumSwitchSts, init-value=0}, provided-interface=PassLumSwitchSts
      PassLumbarBottomWorkSts: nonqueued-sender-com-spec{data-element=PassLumbarBottomWorkSts, init-value=0}, provided-interface=PassLumbarBottomWorkSts
      PassLumbarMidWorkSts: nonqueued-sender-com-spec{data-element=PassLumbarMidWorkSts, init-value=0}, provided-interface=PassLumbarMidWorkSts
      PassLumbarTopWorkSts: nonqueued-sender-com-spec{data-element=PassLumbarTopWorkSts, init-value=0}, provided-interface=PassLumbarTopWorkSts
      PassMassSwitchSts: nonqueued-sender-com-spec{data-element=PassMassSwitchSts, init-value=0}, provided-interface=PassMassSwitchSts
      PassMassageHeatNTC1: nonqueued-sender-com-spec{data-element=PassMassageHeatNTC1, init-value=0}, provided-interface=PassMassageHeatNTC1
      PassMassageHeatNTC{10..12}: nonqueued-sender-com-spec{data-element=PassMassageHeatNTC{10..12}, init-value=0}, provided-interface=PassMassageHeatNTC{10..12}
      PassMassageHeatNTC{2..9}: nonqueued-sender-com-spec{data-element=PassMassageHeatNTC{2..9}, init-value=0}, provided-interface=PassMassageHeatNTC{2..9}
    require port PassPumpCmd: nonqueued-receiver-com-spec{data-element=PassPumpCmd, alive-timeout=0.5, init-value=0}, required-interface=PassPumpCmd
    provide port PassPumpSts: nonqueued-sender-com-spec{data-element=PassPumpSts, init-value=0}, provided-interface=PassPumpSts
    provide port PassSeatBlosterValueSts: nonqueued-sender-com-spec{data-element=PassSeatBlosterValueSts, init-value=0}, provided-interface=PassSeatBlosterValueSts
    require port PassSeatBolsterValueBLCmd: nonqueued-receiver-com-spec{data-element=PassSeatBolsterValueBLCmd, alive-timeout=0.5, init-value=0}, required-interface=PassSeatBolsterValueBLCmd
    provide port PassSeatBolsterValueBLPos: nonqueued-sender-com-spec{data-element=PassSeatBolsterValueBLPos, init-value=0}, provided-interface=PassSeatBolsterValueBLPos
    require port PassSeatBolsterValueBRCmd: nonqueued-receiver-com-spec{data-element=PassSeatBolsterValueBRCmd, alive-timeout=0.5, init-value=0}, required-interface=PassSeatBolsterValueBRCmd
    provide port PassSeatBolsterValueBRPos: nonqueued-sender-com-spec{data-element=PassSeatBolsterValueBRPos, init-value=0}, provided-interface=PassSeatBolsterValueBRPos
    require port PassSeatCushionValue1Cmd: nonqueued-receiver-com-spec{data-element=PassSeatCushionValue1Cmd, alive-timeout=0.5, init-value=0}, required-interface=PassSeatCushionValue1Cmd
    provide port PassSeatCushionValue1Pos: nonqueued-sender-com-spec{data-element=PassSeatCushionValue1Pos, init-value=0}, provided-interface=PassSeatCushionValue1Pos
    require port PassSeatCushionValue2Cmd: nonqueued-receiver-com-spec{data-element=PassSeatCushionValue2Cmd, alive-timeout=0.5, init-value=0}, required-interface=PassSeatCushionValue2Cmd
    provide port PassSeatCushionValue2Pos: nonqueued-sender-com-spec{data-element=PassSeatCushionValue2Pos, init-value=0}, provided-interface=PassSeatCushionValue2Pos
    require port PassSeatCushionValue3Cmd: nonqueued-receiver-com-spec{data-element=PassSeatCushionValue3Cmd, alive-timeout=0.5, init-value=0}, required-interface=PassSeatCushionValue3Cmd
    provide port PassSeatCushionValue3Pos: nonqueued-sender-com-spec{data-element=PassSeatCushionValue3Pos, init-value=0}, provided-interface=PassSeatCushionValue3Pos
    require port PassSeatCushionValue4Cmd: nonqueued-receiver-com-spec{data-element=PassSeatCushionValue4Cmd, alive-timeout=0.5, init-value=0}, required-interface=PassSeatCushionValue4Cmd
    provide port PassSeatCushionValue4Pos: nonqueued-sender-com-spec{data-element=PassSeatCushionValue4Pos, init-value=0}, provided-interface=PassSeatCushionValue4Pos
    require port PassSeatCushionValue5Cmd: nonqueued-receiver-com-spec{data-element=PassSeatCushionValue5Cmd, alive-timeout=0.5, init-value=0}, required-interface=PassSeatCushionValue5Cmd
    provide port PassSeatCushionValue5Pos: nonqueued-sender-com-spec{data-element=PassSeatCushionValue5Pos, init-value=0}, provided-interface=PassSeatCushionValue5Pos
    require port PassSeatCushionValue6Cmd: nonqueued-receiver-com-spec{data-element=PassSeatCushionValue6Cmd, alive-timeout=0.5, init-value=0}, required-interface=PassSeatCushionValue6Cmd
    provide port PassSeatCushionValue6Pos: nonqueued-sender-com-spec{data-element=PassSeatCushionValue6Pos, init-value=0}, provided-interface=PassSeatCushionValue6Pos
    provide port PassSeatCushionValueSts: nonqueued-sender-com-spec{data-element=PassSeatCushionValueSts, init-value=0}, provided-interface=PassSeatCushionValueSts
    provide port PassSeatLumbarBottomPos: nonqueued-sender-com-spec{data-element=PassSeatLumbarBottomPos, init-value=0}, provided-interface=PassSeatLumbarBottomPos
    require port PassSeatLumbarBottomValue3Cmd: nonqueued-receiver-com-spec{data-element=PassSeatLumbarBottomValue3Cmd, alive-timeout=0.5, init-value=0}, required-interface=PassSeatLumbarBottomValue3Cmd
    provide port PassSeatLumbarMidPos: nonqueued-sender-com-spec{data-element=PassSeatLumbarMidPos, init-value=0}, provided-interface=PassSeatLumbarMidPos
    require port PassSeatLumbarMidValue2Cmd: nonqueued-receiver-com-spec{data-element=PassSeatLumbarMidValue2Cmd, alive-timeout=0.5, init-value=0}, required-interface=PassSeatLumbarMidValue2Cmd
    provide port PassSeatLumbarTopPos: nonqueued-sender-com-spec{data-element=PassSeatLumbarTopPos, init-value=0}, provided-interface=PassSeatLumbarTopPos
    require port PassSeatLumbarTopValue1Cmd: nonqueued-receiver-com-spec{data-element=PassSeatLumbarTopValue1Cmd, alive-timeout=0.5, init-value=0}, required-interface=PassSeatLumbarTopValue1Cmd
    provide port PassSeatLumbarValueSts: nonqueued-sender-com-spec{data-element=PassSeatLumbarValueSts, init-value=0}, provided-interface=PassSeatLumbarValueSts
    provide port PassSeatMassFailr: nonqueued-sender-com-spec{data-element=PassSeatMassFailr, init-value=0}, provided-interface=PassSeatMassFailr
    require port PassSeatUpperValueLCmd: nonqueued-receiver-com-spec{data-element=PassSeatUpperValueLCmd, alive-timeout=0.5, init-value=0}, required-interface=PassSeatUpperValueLCmd
    provide port PassSeatUpperValueLPos: nonqueued-sender-com-spec{data-element=PassSeatUpperValueLPos, init-value=0}, provided-interface=PassSeatUpperValueLPos
    require port PassSeatUpperValueMCmd: nonqueued-receiver-com-spec{data-element=PassSeatUpperValueMCmd, alive-timeout=0.5, init-value=0}, required-interface=PassSeatUpperValueMCmd
    provide port PassSeatUpperValueMPos: nonqueued-sender-com-spec{data-element=PassSeatUpperValueMPos, init-value=0}, provided-interface=PassSeatUpperValueMPos
    require port PassSeatUpperValueRCmd: nonqueued-receiver-com-spec{data-element=PassSeatUpperValueRCmd, alive-timeout=0.5, init-value=0}, required-interface=PassSeatUpperValueRCmd
    provide port PassSeatUpperValueRPos: nonqueued-sender-com-spec{data-element=PassSeatUpperValueRPos, init-value=0}, provided-interface=PassSeatUpperValueRPos
    provide port PassSeatUpperValueSts: nonqueued-sender-com-spec{data-element=PassSeatUpperValueSts, init-value=0}, provided-interface=PassSeatUpperValueSts
    12 x require port:
      PassSeatmassgHeat{10..12}Cmd: nonqueued-receiver-com-spec{data-element=PassSeatmassgHeat{10..12}Cmd, alive-timeout=0.5, init-value=0}, required-interface=PassSeatmassgHeat{10..12}Cmd
      PassSeatmassgHeat{1..9}Cmd: nonqueued-receiver-com-spec{data-element=PassSeatmassgHeat{1..9}Cmd, alive-timeout=0.5, init-value=0}, required-interface=PassSeatmassgHeat{1..9}Cmd
    provide port PassSeatmassgHeatCSts: nonqueued-sender-com-spec{data-element=PassSeatmassgHeatCSts, init-value=0}, provided-interface=PassSeatmassgHeatCSts
    12 x require port:
      PassSeatmassgValve{10..12}Cmd: nonqueued-receiver-com-spec{data-element=PassSeatmassgValve{10..12}Cmd, alive-timeout=0.5, init-value=0}, required-interface=PassSeatmassgValve{10..12}Cmd
      PassSeatmassgValve{1..9}Cmd: nonqueued-receiver-com-spec{data-element=PassSeatmassgValve{1..9}Cmd, alive-timeout=0.5, init-value=0}, required-interface=PassSeatmassgValve{1..9}Cmd
    provide port PassSeatmassgValveSts: nonqueued-sender-com-spec{data-element=PassSeatmassgValveSts, init-value=0}, provided-interface=PassSeatmassgValveSts
    provide port PassSystemFailr: nonqueued-sender-com-spec{data-element=PassSystemFailr, init-value=0}, provided-interface=PassSystemFailr
    13 x require port:
      Sec: nonqueued-receiver-com-spec{data-element=Sec, alive-timeout=0.5, init-value=0}, required-interface=Sec
      VC_Data_5E0_CRC: nonqueued-receiver-com-spec{data-element=VC_Data_5E0_CRC, init-value=0}, required-interface=VC_Data_5E0_CRC
      VC_Data_5E0_MsgCntr: nonqueued-receiver-com-spec{data-element=VC_Data_5E0_MsgCntr, init-value=0}, required-interface=VC_Data_5E0_MsgCntr
      VC_Data_5E0_Payload: nonqueued-receiver-com-spec{data-element=VC_Data_5E0_Payload, init-value=0}, required-interface=VC_Data_5E0_Payload
      VehModeDef: nonqueued-receiver-com-spec{data-element=VehModeDef, alive-timeout=0.5, init-value=0}, required-interface=VehModeDef
      VehOdometer: nonqueued-receiver-com-spec{data-element=VehOdometer, alive-timeout=0.5, init-value=0}, required-interface=VehOdometer
      VehSpdSts_Rdnt1: nonqueued-receiver-com-spec{data-element=VehSpdSts_Rdnt1, init-value=0}, required-interface=VehSpdSts_Rdnt1
      VehSpd_Rdnt1: nonqueued-receiver-com-spec{data-element=VehSpd_Rdnt1, init-value=0}, required-interface=VehSpd_Rdnt1
      VehStateDetailed: nonqueued-receiver-com-spec{data-element=VehStateDetailed, alive-timeout=0.5, init-value=0}, required-interface=VehStateDetailed
      VehStateDetailed_SrvSts: nonqueued-receiver-com-spec{data-element=VehStateDetailed_SrvSts, alive-timeout=0.5, init-value=0}, required-interface=VehStateDetailed_SrvSts
      Yr: nonqueued-receiver-com-spec{data-element=Yr, alive-timeout=0.5, init-value=0}, required-interface=Yr
      ZONE_13C_CRC: nonqueued-receiver-com-spec{data-element=ZONE_13C_CRC, alive-timeout=0.5, init-value=0}, required-interface=ZONE_13C_CRC
      ZONE_13C_MsgCntr: nonqueued-receiver-com-spec{data-element=ZONE_13C_MsgCntr, alive-timeout=0.5, init-value=0}, required-interface=ZONE_13C_MsgCntr
